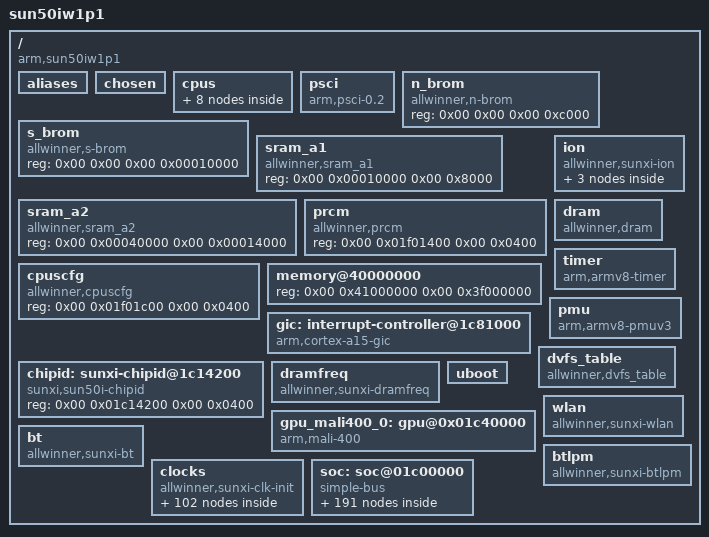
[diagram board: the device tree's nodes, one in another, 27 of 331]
/dts-v1/;

/memreserve/ 0x45000000 0x200000;
/memreserve/ 0x41010000 0x10000;
/memreserve/ 0x41020000 0x800;
/memreserve/ 0x40100000 0x4000;
/memreserve/ 0x40104000 0x1000;
/memreserve/ 0x40105000 0x1000;

/{
    model = "sun50iw1p1";
    compatible = "arm,sun50iw1p1", "arm,sun50iw1p1";
    interrupt-parent = <0x01>;
    #address-cells = <0x02>;
    #size-cells = <0x02>;

    aliases {
		serial0 = &uart0;
		serial1 = &uart1;
		serial2 = &uart2;
		serial3 = &uart3;
		serial4 = &uart4;
        twi0 = &twi0;
		s_twi0 = &s_twi0;
        twi1 = &twi1;
        twi2 = &twi2;
        spi0 = &spi0;
        spi1 = &spi1;
        global_timer0 = &soc_timer0;
        cci0 = &csi_cci0;
        csi_res0 = &csi_res0;
        vfe0 = &csi0;
        mmc0 = &sdc0;
        mmc2 = &sdc2;
        nand0 = &nand0;
        disp = &disp;
        lcd0 = &lcd0;
        hdmi = &hdmi;
        pwm = &pwm;
        pwm0 = &pwm0;
        s_pwm = &s_pwm; 
        spwm0 = &spwm0; 
        boot_disp = &boot_disp; 
    };

    chosen {
        bootargs = "earlyprintk=sunxi-uart,0x01c28000 loglevel=8 initcall_debug=1 console=ttyS0 init=/init";
        linux,initrd-start = <0x00 0x00>;
        linux,initrd-end = <0x00 0x00>;
    };

    cpus {
        #address-cells = <0x02>;
        #size-cells = <0x00>;

        cpu@0 {
            device_type = "cpu";
            compatible = "arm,cortex-a53", "arm,armv8";
            reg = <0x00 0x00>;
            enable-method = "psci";
            cpufreq_tbl = <0x00075300 0x000927c0 0x000afc80 
				0x000c7380 0x000dea80 0x000ea600 
				0x000f6180 0x00101d00 0x0010d880 
				0x00119400 0x00124f80 0x00148200>;
            clock-latency = <0x001e8480>;
            clock-frequency = <0x3c14dc00>;
            cpu-idle-states = <&CPU_SLEEP_0 &CLUSTER_SLEEP_0 &SYS_SLEEP_0>;
        };
        cpu@1 {
            device_type = "cpu";
            compatible = "arm,cortex-a53", "arm,armv8";
            reg = <0x00 0x01>;
            enable-method = "psci";
            clock-frequency = <0x3c14dc00>;
            cpu-idle-states = <&CPU_SLEEP_0 &CLUSTER_SLEEP_0 &SYS_SLEEP_0>;
        };
        cpu@2 {
            device_type = "cpu";
            compatible = "arm,cortex-a53", "arm,armv8";
            reg = <0x00 0x02>;
            enable-method = "psci";
            clock-frequency = <0x3c14dc00>;
            cpu-idle-states = <&CPU_SLEEP_0 &CLUSTER_SLEEP_0 &SYS_SLEEP_0>;
        };
        cpu@3 {
            device_type = "cpu";
            compatible = "arm,cortex-a53", "arm,armv8";
            reg = <0x00 0x03>;
            enable-method = "psci";
            clock-frequency = <0x3c14dc00>;
            cpu-idle-states = <&CPU_SLEEP_0 &CLUSTER_SLEEP_0 &SYS_SLEEP_0>;
        };
        idle-states {
            entry-method = "arm,psci";
            CPU_SLEEP_0: cpu-sleep-0 {
                compatible = "arm,idle-state";
                arm,psci-suspend-param = <0x00010000>;
                entry-latency-us = <0x28>;
                exit-latency-us = <0x64>;
                min-residency-us = <0x96>;
            };
            CLUSTER_SLEEP_0: cluster-sleep-0 {
                compatible = "arm,idle-state";
                arm,psci-suspend-param = <0x01010000>;
                entry-latency-us = <0x01f4>;
                exit-latency-us = <0x03e8>;
                min-residency-us = <0x09c4>;
           };
            SYS_SLEEP_0: sys-sleep-0 {
                compatible = "arm,idle-state";
                arm,psci-suspend-param = <0x02010000>;
                entry-latency-us = <0x03e8>;
                exit-latency-us = <0x07d0>;
                min-residency-us = <0x1194>;
            };
        };
    };
    psci {
        compatible = "arm,psci-0.2";
        method = "smc";
        psci_version = <0x84000000>;
        cpu_suspend = <0xc4000001>;
        cpu_off = <0x84000002>;
        cpu_on = <0xc4000003>;
        affinity_info = <0xc4000004>;
        migrate = <0xc4000005>;
        migrate_info_type = <0x84000006>;
        migrate_info_up_cpu = <0xc4000007>;
        system_off = <0x84000008>;
        system_reset = <0x84000009>;
    };
    n_brom {
        compatible = "allwinner,n-brom";
        reg = <0x00 0x00 0x00 0xc000>;
    };
    s_brom {
        compatible = "allwinner,s-brom";
        reg = <0x00 0x00 0x00 0x00010000>;
    };
    sram_a1 {
        compatible = "allwinner,sram_a1";
        reg = <0x00 0x00010000 0x00 0x8000>;
    };
    sram_a2 {
        compatible = "allwinner,sram_a2";
        reg = <0x00 0x00040000 0x00 0x00014000>;
    };
    prcm {
        compatible = "allwinner,prcm";
        reg = <0x00 0x01f01400 0x00 0x0400>;
    };
    cpuscfg {
        compatible = "allwinner,cpuscfg";
        reg = <0x00 0x01f01c00 0x00 0x0400>;
    };
    ion {
        compatible = "allwinner,sunxi-ion";
        system_contig {
            type = <0x01>;
        };
        cma {
            type = <0x04>;
        };
        system {
            type = <0x00>;
        };
    };
    dram {
        compatible = "allwinner,dram";
        clocks = <&clk_pll_ddr0>, <&clk_pll_ddr1>;
        clock-names = "pll_ddr0", "pll_ddr1";
        dram_clk = <0x02a0>;
        dram_type = <0x03>;
        dram_zq = <0x003b3bdd>;
        dram_odt_en = <0x01>;
        dram_para1 = <0x10e40400>;
        dram_para2 = <0x04000000>;
        dram_mr0 = <0x1c70>;
        dram_mr1 = <0x40>;
        dram_mr2 = <0x18>;
        dram_mr3 = <0x00>;
        dram_tpr0 = <0x0048a192>;
        dram_tpr1 = <0x01c2418d>;
        dram_tpr2 = <0x00076051>;
        dram_tpr3 = <0x050005dc>;
        dram_tpr4 = <0x00>;
        dram_tpr5 = <0x00>;
        dram_tpr6 = <0x00>;
        dram_tpr7 = <0x2a066198>;
        dram_tpr8 = <0x00>;
        dram_tpr9 = <0x00>;
        dram_tpr10 = <0x8808>;
        dram_tpr11 = <0x40a60066>;
        dram_tpr12 = <0x55550000>;
        dram_tpr13 = <0x04000903>;
        device_type = "dram";
    };
    memory@40000000 {
        device_type = "memory";
        reg = <0x00 0x41000000 0x00 0x3f000000>;
    };
    gic: interrupt-controller@1c81000 {
        compatible = "arm,cortex-a15-gic", "arm,cortex-a9-gic";
        #interrupt-cells = <0x03>;
        #address-cells = <0x00>;
        device_type = "gic";
        interrupt-controller;
        reg = <0x00 0x01c81000 0x00 0x1000 
		0x00 0x01c82000 0x00 0x2000 
		0x00 0x01c84000 0x00 0x2000 
		0x00 0x01c86000 0x00 0x2000>;
        interrupts = <0x01 0x09 0x0f04>;
        linux,phandle = <0x01>;
        phandle = <0x01>;
    };
    chipid: sunxi-chipid@1c14200 {
        compatible = "sunxi,sun50i-chipid";
        device_type = "chipid";
        reg = <0x00 0x01c14200 0x00 0x0400>;
    };
    timer {
        compatible = "arm,armv8-timer";
        interrupts = <0x01 0x0d 0xff01 
			0x01 0x0e 0xff01 
			0x01 0x0b 0xff01 
			0x01 0x0a 0xff01>;
        clock-frequency = <0x016e3600>;
    };
    pmu {
        compatible = "arm,armv8-pmuv3";
        interrupts = <0x00 0x78 0x04 
		0x00 0x79 0x04 
		0x00 0x7a 0x04 
		0x00 0x7b 0x04>;
    };
    dvfs_table: dvfs_table {
        compatible = "allwinner,dvfs_table";
        max_freq = <0x44aa2000>;
        min_freq = <0x1c9c3800>;
        lv_count = <0x08>;
        lv1_freq = <0x44aa2000>;
        lv1_volt = <0x0514>;
        lv2_freq = <0x41cdb400>;
        lv2_volt = <0x04ec>;
        lv3_freq = <0x3ef14800>;
        lv3_volt = <0x04d8>;
        lv4_freq = <0x3c14dc00>;
        lv4_volt = <0x04b0>;
        lv5_freq = <0x39387000>;
        lv5_volt = <0x0488>;
        lv6_freq = <0x365c0400>;
        lv6_volt = <0x0460>;
        lv7_freq = <0x30a32c00>;
        lv7_volt = <0x0438>;
        lv8_freq = <0x269fb200>;
        lv8_volt = <0x0410>;
        device_type = "dvfs_table";
    };
    dramfreq {
        compatible = "allwinner,sunxi-dramfreq";
        reg = <0x00 0x01c62000 0x00 
			0x1000 0x00 0x01c63000 
			0x00 0x1000 0x00 
			0x01c20000 0x00 0x0800>;
        clocks = <&clk_pll_ddr0>, <&clk_pll_ddr1>, <&clk_ahb1>;
        status = "okay";
    };

    uboot: uboot {
    };

    gpu_mali400_0: gpu@0x01c40000 {
        compatible = "arm,mali-400", "arm,mali-utgard";
        reg = <0x00 0x01c40000 0x00 0x00010000>;
        interrupts = <0x00 0x61 0x04 
			0x00 0x62 0x04 
			0x00 0x63 0x04 
			0x00 0x64 0x04 
			0x00 0x66 0x04 
			0x00 0x67 0x04>;
        interrupt-names = "IRQGP", "IRQGPMMU", "IRQPP0", 
			"IRQPPMMU0", "IRQPP1", "IRQPPMMU1";
        clocks = <&clk_pll_gpu>, <&clk_gpu>;
        device_type = "gpu_mali400_0";
        normal_freq = <0x0198>;
        scene_ctrl_status = <0x00>;
        temp_ctrl_status = <0x01>;
    };
    wlan: wlan {
        compatible = "allwinner,sunxi-wlan";
        wlan_io_regulator = "vcc-wifi-io";
        wlan_busnum = <0x01>;
        status = "okay";
        device_type = "wlan";
        clocks;
        wlan_power;
        wlan_regon = <&r_pio 0x0b 0x02 0x01 0xffffffff 0xffffffff 0x00>;
        wlan_hostwake = <&r_pio 0x0b 0x03 0x06 0xffffffff 0xffffffff 0x00>;
        efuse_map_path = "wifi_efuse_8189e_for_MB1019Q5.map";
    };
    bt: bt {
        compatible = "allwinner,sunxi-bt";
        bt_io_regulator = "vcc-wifi-io";
        status = "okay";
        device_type = "bt";
        clocks;
        bt_power;
        bt_rst_n = <&r_pio 0x0b 0x04 0x01 0xffffffff 0xffffffff 0x00>;
    };
    btlpm: btlpm {
        compatible = "allwinner,sunxi-btlpm";
        uart_index = <0x01>;
        status = "okay";
        device_type = "btlpm";
        bt_wake = <&r_pio 0x0b 0x06 0x01 0xffffffff 0xffffffff 0x01>;
        bt_hostwake = <&r_pio 0x0b 0x05 0x06 0xffffffff 0xffffffff 0x00>;
    };

	/*** Clocks configuration  ***/
    clocks {
        compatible = "allwinner,sunxi-clk-init";
        device_type = "clocks";
        #address-cells = <0x02>;
        #size-cells = <0x02>;
        ranges;
        reg = <0x00 0x01c20000 0x00 
			0x0320 0x00 0x01f01400 
			0x00 0xb0 0x00 
			0x01f00060 0x00 0x04>;

        clk_losc: losc {
            #clock-cells = <0x00>;
            compatible = "allwinner,fixed-clock";
            clock-frequency = <0x8000>;
            clock-output-names = "losc";
            linux,phandle = <0x0c>;
            phandle = <0x0c>;
        };

        clk_iosc: iosc {
            #clock-cells = <0x00>;
            compatible = "allwinner,fixed-clock";
            clock-frequency = <0x00f42400>;
            clock-output-names = "iosc";
            linux,phandle = <0x0d>;
            phandle = <0x0d>;
        };

        clk_hosc: hosc {
            #clock-cells = <0x00>;
            compatible = "allwinner,fixed-clock";
            clock-frequency = <0x016e3600>;
            clock-output-names = "hosc";
            linux,phandle = <0x06>;
            phandle = <0x06>;
        };

        clk_pll_cpu: pll_cpu {
            #clock-cells = <0x00>;
            compatible = "allwinner,sunxi-pll-clock";
            lock-mode = "new";
            clock-output-names = "pll_cpu";
        };

        clk_pll_audio: pll_audio {
            #clock-cells = <0x00>;
            compatible = "allwinner,sunxi-pll-clock";
            lock-mode = "new";
            assigned-clock-rates = <0x01770000>;
            clock-output-names = "pll_audio";
            linux,phandle = <0x02>;
            phandle = <0x02>;
        };

        clk_pll_video0: pll_video0 {
            #clock-cells = <0x00>;
            compatible = "allwinner,sunxi-pll-clock";
            lock-mode = "new";
            assigned-clock-rates = <0x11b3dc40>;
            clock-output-names = "pll_video0";
            linux,phandle = <0x03>;
            phandle = <0x03>;
        };

        clk_pll_ve: pll_ve {
            #clock-cells = <0x00>;
            compatible = "allwinner,sunxi-pll-clock";
            lock-mode = "new";
            clock-output-names = "pll_ve";
            linux,phandle = <0x16>;
            phandle = <0x16>;
        };
        clk_pll_ddr0: pll_ddr0 {
            #clock-cells = <0x00>;
            compatible = "allwinner,sunxi-pll-clock";
            lock-mode = "new";
            clock-output-names = "pll_ddr0";
            linux,phandle = <0x93>;
            phandle = <0x93>;
        };

        clk_pll_periph0: pll_periph0 {
            #clock-cells = <0x00>;
            compatible = "allwinner,sunxi-pll-clock";
            lock-mode = "new";
            clock-output-names = "pll_periph0";
            linux,phandle = <0x04>;
            phandle = <0x04>;
        };

        clk_pll_periph1: pll_periph1 {
            #clock-cells = <0x00>;
            compatible = "allwinner,sunxi-pll-clock";
            lock-mode = "new";
            clock-output-names = "pll_periph1";
            linux,phandle = <0x05>;
            phandle = <0x05>;
        };

        clk_pll_video1: pll_video1 {
            #clock-cells = <0x00>;
            compatible = "allwinner,sunxi-pll-clock";
            lock-mode = "new";
            assigned-clock-rates = <0x11b3dc40>;
            clock-output-names = "pll_video1";
        };

        clk_pll_gpu: pll_gpu {
            #clock-cells = <0x00>;
            compatible = "allwinner,sunxi-pll-clock";
            lock-mode = "new";
            clock-output-names = "pll_gpu";
            linux,phandle = <0x96>;
            phandle = <0x96>;
        };

        clk_pll_mipi: pll_mipi {
            #clock-cells = <0x00>;
            compatible = "allwinner,sunxi-pll-clock";
            lock-mode = "new";
            clock-output-names = "pll_mipi";
            linux,phandle = <0x08>;
            phandle = <0x08>;
        };
		
        clk_pll_hsic: pll_hsic {
            #clock-cells = <0x00>;
            compatible = "allwinner,sunxi-pll-clock";
            lock-mode = "new";
            clock-output-names = "pll_hsic";
            linux,phandle = <0x3a>;
            phandle = <0x3a>;
        };

        clk_pll_de: pll_de {
            #clock-cells = <0x00>;
            compatible = "allwinner,sunxi-pll-clock";
            lock-mode = "new";
            assigned-clock-rates = <0x11b3dc40>;
            clock-output-names = "pll_de";
            linux,phandle = <0x07>;
            phandle = <0x07>;
        };

        clk_pll_ddr1: pll_ddr1 {
            #clock-cells = <0x00>;
            compatible = "allwinner,sunxi-pll-clock";
            lock-mode = "new";
            clock-output-names = "pll_ddr1";
            linux,phandle = <0x94>;
            phandle = <0x94>;
        };

        clk_pll_audiox8: pll_audiox8 {
            #clock-cells = <0x00>;
            compatible = "allwinner,fixed-factor-clock";
            clocks = <0x02>;
            clock-mult = <0x08>;
            clock-div = <0x01>;
            clock-output-names = "pll_audiox8";
        };

        clk_pll_audiox4: pll_audiox4 {
            #clock-cells = <0x00>;
            compatible = "allwinner,fixed-factor-clock";
            clocks = <0x02>;
            clock-mult = <0x08>;
            clock-div = <0x02>;
            clock-output-names = "pll_audiox4";
            linux,phandle = <0x3c>;
            phandle = <0x3c>;
        };

        clk_pll_audiox2: pll_audiox2 {
            #clock-cells = <0x00>;
            compatible = "allwinner,fixed-factor-clock";
            clocks = <0x02>;
            clock-mult = <0x08>;
            clock-div = <0x04>;
            clock-output-names = "pll_audiox2";
        };

        clk_pll_video0x2: pll_video0x2 {
            #clock-cells = <0x00>;
            compatible = "allwinner,fixed-factor-clock";
            clocks = <0x03>;
            clock-mult = <0x02>;
            clock-div = <0x01>;
            clock-output-names = "pll_video0x2";
        };

        clk_pll_periph0x2: pll_periph0x2 {
            #clock-cells = <0x00>;
            compatible = "allwinner,fixed-factor-clock";
            clocks = <0x04>;
            clock-mult = <0x02>;
            clock-div = <0x01>;
            clock-output-names = "pll_periph0x2";
            linux,phandle = <0x7b>;
            phandle = <0x7b>;
        };

        clk_pll_periph1x2: pll_periph1x2 {
            #clock-cells = <0x00>;
            compatible = "allwinner,fixed-factor-clock";
            clocks = <0x05>;
            clock-mult = <0x02>;
            clock-div = <0x01>;
            clock-output-names = "pll_periph1x2";
            linux,phandle = <0x5a>;
            phandle = <0x5a>;
        };

        clk_pll_periph0d2: pll_periph0d2 {
            #clock-cells = <0x00>;
            compatible = "allwinner,fixed-factor-clock";
            clocks = <0x04>;
            clock-mult = <0x01>;
            clock-div = <0x02>;
            clock-output-names = "pll_periph0d2";
        };

        clk_hoscd2: hoscd2 {
            #clock-cells = <0x00>;
            compatible = "allwinner,fixed-factor-clock";
            clocks = <0x06>;
            clock-mult = <0x01>;
            clock-div = <0x02>;
            clock-output-names = "hoscd2";
        };

        clk_cpu: cpu {
            #clock-cells = <0x00>;
            compatible = "allwinner,sunxi-periph-clock";
            clock-output-names = "cpu";
        };

        clk_cpuapb: cpuapb {
            #clock-cells = <0x00>;
            compatible = "allwinner,sunxi-periph-clock";
            clock-output-names = "cpuapb";
        };

        clk_axi: axi {
            #clock-cells = <0x00>;
            compatible = "allwinner,sunxi-periph-clock";
            clock-output-names = "axi";
        };

        clk_pll_periphahb0: pll_periphahb0 {
            #clock-cells = <0x00>;
            compatible = "allwinner,sunxi-periph-clock";
            clock-output-names = "pll_periphahb0";
        };

        clk_ahb1: ahb1 {
            #clock-cells = <0x00>;
            compatible = "allwinner,sunxi-periph-clock";
            clock-output-names = "ahb1";
            linux,phandle = <0x95>;
            phandle = <0x95>;
        };

        clk_apb1: apb1 {
            #clock-cells = <0x00>;
            compatible = "allwinner,sunxi-periph-clock";
            clock-output-names = "apb1";
        };

        clk_apb2: apb2 {
            #clock-cells = <0x00>;
            compatible = "allwinner,sunxi-periph-clock";
            clock-output-names = "apb2";
            linux,phandle = <0x7e>;
            phandle = <0x7e>;
        };

        clk_ahb2: ahb2 {
            #clock-cells = <0x00>;
            compatible = "allwinner,sunxi-periph-clock";
            clock-output-names = "ahb2";
        };

        clk_ths: ths {
            #clock-cells = <0x00>;
            compatible = "allwinner,sunxi-periph-clock";
            clock-output-names = "ths";
            linux,phandle = <0x84>;
            phandle = <0x84>;
        };

        clk_nand: nand {
            #clock-cells = <0x00>;
            compatible = "allwinner,sunxi-periph-clock";
            clock-output-names = "nand";
            linux,phandle = <0x80>;
            phandle = <0x80>;
        };
		
        clk_sdmmc0_mod: sdmmc0_mod {
            #clock-cells = <0x00>;
            compatible = "allwinner,sunxi-periph-clock";
            clock-output-names = "sdmmc0_mod";
            linux,phandle = <0x60>;
            phandle = <0x60>;
        };

        clk_sdmmc0_bus: sdmmc0_bus {
            #clock-cells = <0x00>;
            compatible = "allwinner,sunxi-periph-clock";
            clock-output-names = "sdmmc0_bus";
            linux,phandle = <0x61>;
            phandle = <0x61>;
        };

        clk_sdmmc0_rst: sdmmc0_rst {
            #clock-cells = <0x00>;
            compatible = "allwinner,sunxi-periph-clock";
            clock-output-names = "sdmmc0_rst";
            linux,phandle = <0x62>;
            phandle = <0x62>;
        };

        clk_sdmmc1_mod: sdmmc1_mod {
            #clock-cells = <0x00>;
            compatible = "allwinner,sunxi-periph-clock";
            clock-output-names = "sdmmc1_mod";
            linux,phandle = <0x65>;
            phandle = <0x65>;
        };

        clk_sdmmc1_bus: sdmmc1_bus {
            #clock-cells = <0x00>;
            compatible = "allwinner,sunxi-periph-clock";
            clock-output-names = "sdmmc1_bus";
            linux,phandle = <0x66>;
            phandle = <0x66>;
        };

        clk_sdmmc1_rst: sdmmc1_rst {
            #clock-cells = <0x00>;
            compatible = "allwinner,sunxi-periph-clock";
            clock-output-names = "sdmmc1_rst";
            linux,phandle = <0x67>;
            phandle = <0x67>;
        };
		
        clk_sdmmc2_mod: sdmmc2_mod {
            #clock-cells = <0x00>;
            compatible = "allwinner,sunxi-periph-clock";
            clock-output-names = "sdmmc2_mod";
            linux,phandle = <0x5b>;
            phandle = <0x5b>;
        };

        clk_sdmmc2_bus: sdmmc2_bus {
            #clock-cells = <0x00>;
            compatible = "allwinner,sunxi-periph-clock";
            clock-output-names = "sdmmc2_bus";
            linux,phandle = <0x5c>;
            phandle = <0x5c>;
        };

        clk_sdmmc2_rst: sdmmc2_rst {
            #clock-cells = <0x00>;
            compatible = "allwinner,sunxi-periph-clock";
            clock-output-names = "sdmmc2_rst";
            linux,phandle = <0x5d>;
            phandle = <0x5d>;
        };

        clk_ts: ts {
            #clock-cells = <0x00>;
            compatible = "allwinner,sunxi-periph-clock";
            clock-output-names = "ts";
        };

        clk_ce: ce {
            #clock-cells = <0x00>;
            compatible = "allwinner,sunxi-periph-clock";
            clock-output-names = "ce";
            linux,phandle = <0x7a>;
            phandle = <0x7a>;
        };

        clk_spi0: spi0 {
            #clock-cells = <0x00>;
            compatible = "allwinner,sunxi-periph-clock";
            clock-output-names = "spi0";
            linux,phandle = <0x52>;
            phandle = <0x52>;
        };

        clk_spi1: spi1 {
            #clock-cells = <0x00>;
            compatible = "allwinner,sunxi-periph-clock";
            clock-output-names = "spi1";
            linux,phandle = <0x56>;
            phandle = <0x56>;
        };

        clk_i2s0: i2s0 {
            #clock-cells = <0x00>;
            compatible = "allwinner,sunxi-periph-clock";
            clock-output-names = "i2s0";
            linux,phandle = <0x42>;
            phandle = <0x42>;
        };

        clk_i2s1: i2s1 {
            #clock-cells = <0x00>;
            compatible = "allwinner,sunxi-periph-clock";
            clock-output-names = "i2s1";
            linux,phandle = <0x47>;
            phandle = <0x47>;
        };

        clk_i2s2: i2s2 {
            #clock-cells = <0x00>;
            compatible = "allwinner,sunxi-periph-clock";
            clock-output-names = "i2s2";
            linux,phandle = <0x48>;
            phandle = <0x48>;
        };

        clk_spdif: spdif {
            #clock-cells = <0x00>;
            compatible = "allwinner,sunxi-periph-clock";
            clock-output-names = "spdif";
            linux,phandle = <0x49>;
            phandle = <0x49>;
        };

        clk_usbphy0: usbphy0 {
            #clock-cells = <0x00>;
            compatible = "allwinner,sunxi-periph-clock";
            clock-output-names = "usbphy0";
            linux,phandle = <0x32>;
            phandle = <0x32>;
        };

        clk_usbphy1: usbphy1 {
            #clock-cells = <0x00>;
            compatible = "allwinner,sunxi-periph-clock";
            clock-output-names = "usbphy1";
            linux,phandle = <0x36>;
            phandle = <0x36>;
        };

        clk_usbhsic: usbhsic {
            #clock-cells = <0x00>;
            compatible = "allwinner,sunxi-periph-clock";
            clock-output-names = "usbhsic";
            linux,phandle = <0x38>;
            phandle = <0x38>;
        };

        clk_usbhsic12m: usbhsic12m {
            #clock-cells = <0x00>;
            compatible = "allwinner,sunxi-periph-clock";
            clock-output-names = "usbhsic12m";
            linux,phandle = <0x39>;
            phandle = <0x39>;
        };

        clk_usbohci1: usbohci1 {
            #clock-cells = <0x00>;
            compatible = "allwinner,sunxi-periph-clock";
            clock-output-names = "usbohci1";
            linux,phandle = <0x3b>;
            phandle = <0x3b>;
        };

        clk_usbohci0: usbohci0 {
            #clock-cells = <0x00>;
            compatible = "allwinner,sunxi-periph-clock";
            clock-output-names = "usbohci0";
            linux,phandle = <0x35>;
            phandle = <0x35>;
        };

        clk_de: de {
            #clock-cells = <0x00>;
            compatible = "allwinner,sunxi-periph-clock";
            assigned-clock-parents = <0x07>;
            assigned-clock-rates = <0x11b3dc40>;
            clock-output-names = "de";
            linux,phandle = <0x6a>;
            phandle = <0x6a>;
        };

        clk_tcon0: tcon0 {
            #clock-cells = <0x00>;
            compatible = "allwinner,sunxi-periph-clock";
            assigned-clock-parents = <0x08>;
            clock-output-names = "tcon0";
            linux,phandle = <0x6b>;
            phandle = <0x6b>;
        };

        clk_tcon1: tcon1 {
            #clock-cells = <0x00>;
            compatible = "allwinner,sunxi-periph-clock";
            assigned-clock-parents = <0x03>;
            clock-output-names = "tcon1";
            linux,phandle = <0x6e>;
            phandle = <0x6e>;
        };

        clk_deinterlace: deinterlace {
            #clock-cells = <0x00>;
            compatible = "allwinner,sunxi-periph-clock";
            clock-output-names = "deinterlace";
            linux,phandle = <0x7c>;
            phandle = <0x7c>;
        };

        clk_csi_s: csi_s {
            #clock-cells = <0x00>;
            compatible = "allwinner,sunxi-periph-clock";
            clock-output-names = "csi_s";
            linux,phandle = <0x73>;
            phandle = <0x73>;
        };

        clk_csi_m: csi_m {
            #clock-cells = <0x00>;
            compatible = "allwinner,sunxi-periph-clock";
            clock-output-names = "csi_m";
            linux,phandle = <0x74>;
            phandle = <0x74>;
        };

        clk_csi_misc: csi_misc {
            #clock-cells = <0x00>;
            compatible = "allwinner,sunxi-periph-clock";
            clock-output-names = "csi_misc";
            linux,phandle = <0x75>;
            phandle = <0x75>;
        };

        clk_ve: ve {
            #clock-cells = <0x00>;
            compatible = "allwinner,sunxi-periph-clock";
            clock-output-names = "ve";
            linux,phandle = <0x17>;
            phandle = <0x17>;
        };

        clk_adda: adda {
            #clock-cells = <0x00>;
            compatible = "allwinner,sunxi-periph-clock";
            clock-output-names = "adda";
            linux,phandle = <0x41>;
            phandle = <0x41>;
        };

        clk_addax4: addax4 {
            #clock-cells = <0x00>;
            compatible = "allwinner,sunxi-periph-clock";
            clock-output-names = "addax4";
        };

        clk_avs: avs {
            #clock-cells = <0x00>;
            compatible = "allwinner,sunxi-periph-clock";
            clock-output-names = "avs";
        };

        clk_hdmi: hdmi {
            #clock-cells = <0x00>;
            compatible = "allwinner,sunxi-periph-clock";
            assigned-clock-parents = <0x03>;
            clock-output-names = "hdmi";
            linux,phandle = <0x6f>;
            phandle = <0x6f>;
        };

        clk_hdmi_slow: hdmi_slow {
            #clock-cells = <0x00>;
            compatible = "allwinner,sunxi-periph-clock";
            clock-output-names = "hdmi_slow";
            linux,phandle = <0x70>;
            phandle = <0x70>;
        };

        clk_mbus: mbus {
            #clock-cells = <0x00>;
            compatible = "allwinner,sunxi-periph-clock";
            clock-output-names = "mbus";
        };

        clk_mipidsi: mipidsi {
            #clock-cells = <0x00>;
            compatible = "allwinner,sunxi-periph-clock";
            clock-output-names = "mipidsi";
            linux,phandle = <0x6d>;
            phandle = <0x6d>;
        };

        clk_gpu: gpu {
            #clock-cells = <0x00>;
            compatible = "allwinner,sunxi-periph-clock";
            clock-output-names = "gpu";
            linux,phandle = <0x97>;
            phandle = <0x97>;
        };

        clk_usbehci_16: usbehci_16 {
            #clock-cells = <0x00>;
            compatible = "allwinner,sunxi-periph-clock";
            clock-output-names = "usbohci_16";
        };

        clk_usbehci1: usbehci1 {
            #clock-cells = <0x00>;
            compatible = "allwinner,sunxi-periph-clock";
            clock-output-names = "usbehci1";
            linux,phandle = <0x37>;
            phandle = <0x37>;
        };

        clk_usbehci0: usbehci0 {
            #clock-cells = <0x00>;
            compatible = "allwinner,sunxi-periph-clock";
            clock-output-names = "usbehci0";
            linux,phandle = <0x34>;
            phandle = <0x34>;
        };

        clk_usbotg: usbotg {
            #clock-cells = <0x00>;
            compatible = "allwinner,sunxi-periph-clock";
            clock-output-names = "usbotg";
            linux,phandle = <0x33>;
            phandle = <0x33>;
        };

        clk_gmac: gmac {
            #clock-cells = <0x00>;
            compatible = "allwinner,sunxi-periph-clock";
            clock-output-names = "gmac";
            linux,phandle = <0x8f>;
            phandle = <0x8f>;
        };

        clk_sdram: sdram {
            #clock-cells = <0x00>;
            compatible = "allwinner,sunxi-periph-clock";
            clock-output-names = "sdram";
        };

        clk_dma: dma {
            #clock-cells = <0x00>;
            compatible = "allwinner,sunxi-periph-clock";
            clock-output-names = "dma";
            linux,phandle = <0x0b>;
            phandle = <0x0b>;
        };

        clk_hwspinlock_rst: hwspinlock_rst {
            #clock-cells = <0x00>;
            compatible = "allwinner,sunxi-periph-clock";
            clock-output-names = "hwspinlock_rst";
            linux,phandle = <0x0f>;
            phandle = <0x0f>;
        };

        clk_hwspinlock_bus: hwspinlock_bus {
            #clock-cells = <0x00>;
            compatible = "allwinner,sunxi-periph-clock";
            clock-output-names = "hwspinlock_bus";
            linux,phandle = <0x10>;
            phandle = <0x10>;
        };

        clk_msgbox: msgbox {
            #clock-cells = <0x00>;
            compatible = "allwinner,sunxi-periph-clock";
            clock-output-names = "msgbox";
            linux,phandle = <0x0e>;
            phandle = <0x0e>;
        };

        clk_lvds: lvds {
            #clock-cells = <0x00>;
            compatible = "allwinner,sunxi-periph-clock";
            clock-output-names = "lvds";
            linux,phandle = <0x6c>;
            phandle = <0x6c>;
        };

        clk_uart0: uart0 {
            #clock-cells = <0x00>;
            compatible = "allwinner,sunxi-periph-clock";
            clock-output-names = "uart0";
            linux,phandle = <0x18>;
            phandle = <0x18>;
        };

        clk_uart1: uart1 {
            #clock-cells = <0x00>;
            compatible = "allwinner,sunxi-periph-clock";
            clock-output-names = "uart1";
            linux,phandle = <0x1b>;
            phandle = <0x1b>;
        };

        clk_uart2: uart2 {
            #clock-cells = <0x00>;
            compatible = "allwinner,sunxi-periph-clock";
            clock-output-names = "uart2";
            linux,phandle = <0x1e>;
            phandle = <0x1e>;
        };

        clk_uart3: uart3 {
            #clock-cells = <0x00>;
            compatible = "allwinner,sunxi-periph-clock";
            clock-output-names = "uart3";
            linux,phandle = <0x21>;
            phandle = <0x21>;
        };

        clk_uart4: uart4 {
            #clock-cells = <0x00>;
            compatible = "allwinner,sunxi-periph-clock";
            clock-output-names = "uart4";
            linux,phandle = <0x24>;
            phandle = <0x24>;
        };

        clk_scr: scr {
            #clock-cells = <0x00>;
            compatible = "allwinner,sunxi-periph-clock";
            clock-output-names = "scr";
            linux,phandle = <0x7d>;
            phandle = <0x7d>;
        };

        clk_twi0: twi0 {
            #clock-cells = <0x00>;
            compatible = "allwinner,sunxi-periph-clock";
            clock-output-names = "twi0";
            linux,phandle = <0x27>;
            phandle = <0x27>;
        };

        clk_twi1: twi1 {
            #clock-cells = <0x00>;
            compatible = "allwinner,sunxi-periph-clock";
            clock-output-names = "twi1";
            linux,phandle = <0x2a>;
            phandle = <0x2a>;
        };

        clk_twi2: twi2 {
            #clock-cells = <0x00>;
            compatible = "allwinner,sunxi-periph-clock";
            clock-output-names = "twi2";
            linux,phandle = <0x2d>;
            phandle = <0x2d>;
        };

        clk_twi3: twi3 {
            #clock-cells = <0x00>;
            compatible = "allwinner,sunxi-periph-clock";
            clock-output-names = "twi3";
        };

        clk_pio: pio {
            #clock-cells = <0x00>;
            compatible = "allwinner,sunxi-periph-clock";
            clock-output-names = "pio";
            linux,phandle = <0x0a>;
            phandle = <0x0a>;
        };

        clk_cpurcir: cpurcir {
            #clock-cells = <0x00>;
            compatible = "allwinner,sunxi-periph-cpus-clock";
            clock-output-names = "cpurcir";
            linux,phandle = <0x12>;
            phandle = <0x12>;
        };

        clk_cpurpio: cpurpio {
            #clock-cells = <0x00>;
            compatible = "allwinner,sunxi-periph-cpus-clock";
            clock-output-names = "cpurpio";
            linux,phandle = <0x09>;
            phandle = <0x09>;
        };

        clk_cpurpll_peri0: cpurpll_peri0 {
            #clock-cells = <0x00>;
            compatible = "allwinner,sunxi-periph-cpus-clock";
            clock-output-names = "cpurpll_peri0";
        };

        clk_cpurcpus: cpurcpus {
            #clock-cells = <0x00>;
            compatible = "allwinner,sunxi-periph-cpus-clock";
            clock-output-names = "cpurcpus";
        };

        clk_cpurahbs: cpurahbs {
            #clock-cells = <0x00>;
            compatible = "allwinner,sunxi-periph-cpus-clock";
            clock-output-names = "cpurahbs";
        };

        clk_cpuapbs: cpurapbs {
            #clock-cells = <0x00>;
            compatible = "allwinner,sunxi-periph-cpus-clock";
            clock-output-names = "cpurapbs";
        };

        clk_losc_out: losc_out {
            #clock-cells = <0x00>;
            compatible = "allwinner,sunxi-periph-cpus-clock";
            clock-output-names = "losc_out";
            linux,phandle = <0x98>;
            phandle = <0x98>;
        };
    };

	/***  SOC Configuration ***/
    soc: soc@01c00000 {
        compatible = "simple-bus";
        #address-cells = <0x02>;
        #size-cells = <0x02>;
        ranges;
        device_type = "soc";

		/*** Pin control (r_pio) ***/
        r_pio: pinctrl@01f02c00 {
            compatible = "allwinner,sun50i-r-pinctrl";
            reg = <0x00 0x01f02c00 0x00 0x0400>;
            interrupts = <0x00 0x2d 0x04>;
            clocks = <0x09>;
            device_type = "r_pio";
            gpio-controller;
            interrupt-controller;
            #interrupt-cells = <0x02>;
            #size-cells = <0x00>;
            #gpio-cells = <0x06>;
            linux,phandle = <0x79>;
            phandle = <0x79>;

            s_cir0_pins_a: s_cir0@0 {
                allwinner,pins = "L11";
                allwinner,function = "s_cir0";
                allwinner,muxsel = <0x02>;
                allwinner,drive = <0x02>;
                allwinner,pull = <0x01>;
                linux,phandle = <0x11>;
                phandle = <0x11>;
            };

            spwm0_pins_a: spwm0@0 {
                linux,phandle = <0xaf>;
                phandle = <0xaf>;
                allwinner,pins = "PL10";
                allwinner,function = "spwm0";
                allwinner,pname = "pwm_positive";
                allwinner,muxsel = <0x02>;
                allwinner,pull = <0x00>;
                allwinner,drive = <0xffffffff>;
                allwinner,data = <0xffffffff>;
            };

            spwm0_pins_b: spwm0@1 {
                linux,phandle = <0xb0>;
                phandle = <0xb0>;
                allwinner,pins = "PL10";
                allwinner,function = "spwm0";
                allwinner,pname = "pwm_positive";
                allwinner,muxsel = <0x07>;
                allwinner,pull = <0x00>;
                allwinner,drive = <0xffffffff>;
                allwinner,data = <0xffffffff>;
            };

            s_uart0_pins_a: s_uart0@0 {
                linux,phandle = <0xb6>;
                phandle = <0xb6>;
                allwinner,pins = "PL2", "PL3";
                allwinner,function = "s_uart0";
                allwinner,pname = "s_uart0_tx", "s_uart0_rx";
                allwinner,muxsel = <0x02>;
                allwinner,pull = <0xffffffff>;
                allwinner,drive = <0xffffffff>;
                allwinner,data = <0xffffffff>;
            };

            s_rsb0_pins_a: s_rsb0@0 {
                linux,phandle = <0xb7>;
                phandle = <0xb7>;
                allwinner,pins = "PL0", "PL1";
                allwinner,function = "s_rsb0";
                allwinner,pname = "s_rsb0_sck", "s_rsb0_sda";
                allwinner,muxsel = <0x02>;
                allwinner,pull = <0x01>;
                allwinner,drive = <0x02>;
                allwinner,data = <0xffffffff>;
            };

            s_jtag0_pins_a: s_jtag0@0 {
                linux,phandle = <0xb8>;
                phandle = <0xb8>;
                allwinner,pins = "PL4", "PL5", "PL6", "PL7";
                allwinner,function = "s_jtag0";
                allwinner,pname = "s_jtag0_tms", "s_jtag0_tck", "s_jtag0_tdo", "s_jtag0_tdi";
                allwinner,muxsel = <0x02>;
                allwinner,pull = <0x00>;
                allwinner,drive = <0x01>;
                allwinner,data = <0xffffffff>;
            };

            s_twi0_pins_a: s_twi0@0 {
                allwinner,pins = "PL8", "PL9";
                allwinner,function = "s_twi0";
                allwinner,pname = "s_twi0_scl", "s_twi0_sda";
                allwinner,muxsel = <0x02>;
                allwinner,pull = <0x00>;
                allwinner,drive = <0x01>;
                allwinner,data = <0xffffffff>;
            };

            s_twi0_pins_b: s_twi0@1 {
                allwinner,pins = "PL8", "PL9";
                allwinner,function = "io_disabled";
                allwinner,muxsel = <0x07>;
                allwinner,drive = <0x01>;
                allwinner,pull = <0x00>;
            };


        };

		/*** Pin control (pio) ***/
        pio: pinctrl@01c20800 {
            compatible = "allwinner,sun50i-pinctrl";
            reg = <0x00 0x01c20800 0x00 0x0400>;
            interrupts = <0x00 0x0b 0x04 
				0x00 0x11 0x04 
				0x00 0x15 0x04>;
            device_type = "pio";
            clocks = <0x0a>;
            gpio-controller;
            interrupt-controller;
            #interrupt-cells = <0x02>;
            #size-cells = <0x00>;
            #gpio-cells = <0x06>;
            linux,phandle = <0x30>;
            phandle = <0x30>;

            uart0_pins_b: uart0@1 {
                allwinner,pins = "PB8", "PB9";
                allwinner,function = "io_disabled";
                allwinner,muxsel = <0x07>;
                allwinner,drive = <0x01>;
                allwinner,pull = <0x01>;
                linux,phandle = <0x1a>;
                phandle = <0x1a>;
            };

            uart1_pins_b: uart1@1 {
                allwinner,pins = "PG6", "PG7", "PG8", "PG9";
                allwinner,function = "io_disabled";
                allwinner,muxsel = <0x07>;
                allwinner,drive = <0x01>;
                allwinner,pull = <0x01>;
                linux,phandle = <0x1d>;
                phandle = <0x1d>;
            };

            uart2_pins_b: uart2@1 {
                allwinner,pins = "PB0", "PB1", "PB2", "PB3";
                allwinner,function = "io_disabled";
                allwinner,muxsel = <0x07>;
                allwinner,drive = <0x01>;
                allwinner,pull = <0x01>;
                linux,phandle = <0x20>;
                phandle = <0x20>;
            };

            uart3_pins_b: uart3@1 {
                allwinner,pins = "PH4", "PH5", "PH6", "PH7";
                allwinner,function = "io_disabled";
                allwinner,muxsel = <0x07>;
                allwinner,drive = <0x01>;
                allwinner,pull = <0x01>;
                linux,phandle = <0x23>;
                phandle = <0x23>;
            };

            uart4_pins_b: uart4@1 {
                allwinner,pins = "PD2", "PD3", "PD4", "PD5";
                allwinner,function = "io_disabled";
                allwinner,muxsel = <0x07>;
                allwinner,drive = <0x01>;
                allwinner,pull = <0x01>;
                linux,phandle = <0x26>;
                phandle = <0x26>;
            };

            twi0_pins_b: twi0@1 {
                allwinner,pins = "PH0", "PH1";
                allwinner,function = "io_disabled";
                allwinner,muxsel = <0x07>;
                allwinner,drive = <0x01>;
                allwinner,pull = <0x00>;
                linux,phandle = <0x29>;
                phandle = <0x29>;
            };

            twi1_pins_b: twi1@1 {
                allwinner,pins = "PH2", "PH3";
                allwinner,function = "io_disabled";
                allwinner,muxsel = <0x07>;
                allwinner,drive = <0x01>;
                allwinner,pull = <0x00>;
                linux,phandle = <0x2c>;
                phandle = <0x2c>;
            };

            twi2_pins_b: twi2@1 {
                allwinner,pins = "PE14", "PE15";
                allwinner,function = "io_disabled";
                allwinner,muxsel = <0x07>;
                allwinner,drive = <0x01>;
                allwinner,pull = <0x00>;
                linux,phandle = <0x2f>;
                phandle = <0x2f>;
            };

            spi0_pins_c: spi0@2 {
                allwinner,pins = "PC3", "PC2", "PC0", "PC1";
                allwinner,function = "io_disabled";
                allwinner,muxsel = <0x07>;
                allwinner,drive = <0x01>;
                allwinner,pull = <0x00>;
                linux,phandle = <0x55>;
                phandle = <0x55>;
            };

            spi1_pins_c: spi1@2 {
                allwinner,pins = "PD0", "PD1", "PD2", "PD3";
                allwinner,function = "io_disabled";
                allwinner,muxsel = <0x07>;
                allwinner,drive = <0x01>;
                allwinner,pull = <0x00>;
                linux,phandle = <0x59>;
                phandle = <0x59>;
            };

            sdc0_pins_b: sdc0@1 {
                allwinner,pins = "PF0", "PF1", "PF2", "PF3", "PF4", "PF5";
                allwinner,function = "io_disabled";
                allwinner,muxsel = <0x07>;
                allwinner,drive = <0x01>;
                allwinner,pull = <0x01>;
                linux,phandle = <0x64>;
                phandle = <0x64>;
            };

            sdc1_pins_b: sdc1@1 {
                allwinner,pins = "PG0", "PG1", "PG2", "PG3", "PG4", "PG5";
                allwinner,function = "io_disabled";
                allwinner,muxsel = <0x07>;
                allwinner,drive = <0x01>;
                allwinner,pull = <0x01>;
                linux,phandle = <0x69>;
                phandle = <0x69>;
            };

            sdc2_pins_b: sdc2@1 {
                allwinner,pins = "PC1", "PC5", "PC6", "PC8", 
					"PC9", "PC10", "PC11", "PC12", 
					"PC13", "PC14", "PC15", "PC16";
                allwinner,function = "io_disabled";
                allwinner,muxsel = <0x07>;
                allwinner,drive = <0x01>;
                allwinner,pull = <0x01>;
                linux,phandle = <0x5f>;
                phandle = <0x5f>;
            };

            daudio0_pins_a: daudio0@0 {
                allwinner,pins = "PB6", "PB3", "PB4", "PB5", "PB7";
                allwinner,function = "pcm0";
                allwinner,muxsel = <0x03>;
                allwinner,drive = <0x01>;
                allwinner,pull = <0x00>;
                linux,phandle = <0x43>;
                phandle = <0x43>;
            };

            daudio0_pins_b: daudio0_sleep@0 {
                allwinner,pins = "PB6", "PB3", "PB4", "PB5", "PB7";
                allwinner,function = "io_disabled";
                allwinner,muxsel = <0x07>;
                allwinner,drive = <0x01>;
                allwinner,pull = <0x00>;
                linux,phandle = <0x44>;
                phandle = <0x44>;
            };

            daudio1_pins_a: daudio1@0 {
                allwinner,pins = "PG10", "PG11", "PG12", "PG13";
                allwinner,function = "pcm1";
                allwinner,muxsel = <0x03>;
                allwinner,drive = <0x01>;
                allwinner,pull = <0x00>;
                linux,phandle = <0x45>;
                phandle = <0x45>;
            };

            daudio1_pins_b: daudio1_sleep@0 {
                allwinner,pins = "PG10", "PG11", "PG12", "PG13";
                allwinner,function = "io_disabled";
                allwinner,muxsel = <0x07>;
                allwinner,drive = <0x01>;
                allwinner,pull = <0x00>;
                linux,phandle = <0x46>;
                phandle = <0x46>;
            };

			aif2_pins_a: aif2@0 {
				allwinner,pins = "PB6", "PB4", "PB5", "PB7";
				allwinner,function = "aif2";
				allwinner,muxsel = <2>;
				allwinner,drive = <1>;
				allwinner,pull = <0>;
			};

            aif2_pins_b: aif2_sleep@0 {
                allwinner,pins = "PB6", "PB4", "PB5", "PB7";
                allwinner,function = "io_disabled";
                allwinner,muxsel = <0x07>;
                allwinner,drive = <0x01>;
                allwinner,pull = <0x00>;
                linux,phandle = <0x3f>;
                phandle = <0x3f>;
            };

            aif3_pins_a: aif3@0 {
                allwinner,pins = "PG10", "PG11", "PG12", "PG13";
                allwinner,function = "aif3";
                allwinner,muxsel = <0x02>;
                allwinner,drive = <0x01>;
                allwinner,pull = <0x00>;
                linux,phandle = <0x3e>;
                phandle = <0x3e>;
            };

            aif3_pins_b: aif3_sleep@0 {
                allwinner,pins = "PG10", "PG11", "PG12", "PG13";
                allwinner,function = "io_disabled";
                allwinner,muxsel = <0x07>;
                allwinner,drive = <0x01>;
                allwinner,pull = <0x00>;
                linux,phandle = <0x40>;
                phandle = <0x40>;
            };

            spdif_pins_a: spdif@0 {
                allwinner,pins = "PH8";
                allwinner,function = "spdif0";
                allwinner,muxsel = <0x02>;
                allwinner,drive = <0x01>;
                allwinner,pull = <0x00>;
                linux,phandle = <0x4a>;
                phandle = <0x4a>;
            };

            spdif_pins_b: spdif_sleep@0 {
                allwinner,pins = "PH8";
                allwinner,function = "io_disabled";
                allwinner,muxsel = <0x07>;
                allwinner,drive = <0x01>;
                allwinner,pull = <0x00>;
                linux,phandle = <0x4b>;
                phandle = <0x4b>;
            };

            csi0_pins_b: csi0_sleep@0 {
                allwinner,pins = "PE0", "PE2", "PE3", "PE4", 
					"PE5", "PE6", "PE7", "PE8", 
					"PE9", "PE10", "PE11", "PE12", "PE13";
                allwinner,pname = "csi0_pck", "csi0_hsync", "csi0_vsync", 
					"csi0_d0", "csi0_d1", "csi0_d2", "csi0_d3", 
					"csi0_d4", "csi0_d5", "csi0_d6", "csi0_d7", 
					"csi0_sck", "csi0_sda";
                allwinner,function = "io_disabled";
                allwinner,muxsel = <0x07>;
                allwinner,drive = <0x01>;
                allwinner,pull = <0x00>;
                allwinner,data = <0x00>;
                linux,phandle = <0x77>;
                phandle = <0x77>;
            };

            scr_pins_a: smartcard@0 {
                allwinner,pins = "PB1", "PB4", "PB5", "PB6", "PB7";
                allwinner,function = "sim0";
                allwinner,muxsel = <0x05>;
                allwinner,drive = <0x01>;
                allwinner,pull = <0x01>;
                linux,phandle = <0x7f>;
                phandle = <0x7f>;
            };

            nand0_pins_c: nand0@2 {
                allwinner,pins = "PC0", "PC1", "PC2", "PC3", 
					"PC4", "PC5", "PC6", "PC7", 
					"PC8", "PC9", "PC10", "PC11", 
					"PC12", "PC13", "PC14", "PC15", 
					"PC16", "PC17", "PC18";
                allwinner,function = "io_disabled";
                allwinner,muxsel = <0x07>;
                allwinner,drive = <0x01>;
                allwinner,pull = <0x00>;
                linux,phandle = <0x83>;
                phandle = <0x83>;
            };

            card0_boot_para_pins_a: card0_boot_para@0 {
                linux,phandle = <0x99>;
                phandle = <0x99>;
                allwinner,pins = "PF0", "PF1", "PF2", "PF3", "PF4", "PF5";
                allwinner,function = "card0_boot_para";
                allwinner,pname = "sdc_d1", "sdc_d0", "sdc_clk", "sdc_cmd", 
					"sdc_d3", "sdc_d2";
                allwinner,muxsel = <0x02>;
                allwinner,pull = <0x01>;
                allwinner,drive = <0x02>;
                allwinner,data = <0xffffffff>;
            };

            card2_boot_para_pins_a: card2_boot_para@0 {
                linux,phandle = <0x9a>;
                phandle = <0x9a>;
                allwinner,pins = "PC1", "PC5", "PC6", "PC8", 
					"PC9", "PC10", "PC11", "PC12", 
					"PC13", "PC14", "PC15", "PC16";
                allwinner,function = "card2_boot_para";
                allwinner,pname = "sdc_ds", "sdc_clk", "sdc_cmd", "sdc_d0", 
					"sdc_d1", "sdc_d2", "sdc_d3", "sdc_d4", 
					"sdc_d5", "sdc_d6", "sdc_d7", "sdc_emmc_rst";
                allwinner,muxsel = <0x03>;
                allwinner,pull = <0x01>;
                allwinner,drive = <0x03>;
                allwinner,data = <0xffffffff>;
            };

            twi_para_pins_a: twi_para@0 {
                linux,phandle = <0x9b>;
                phandle = <0x9b>;
                allwinner,pins = "PH0", "PH1";
                allwinner,function = "twi_para";
                allwinner,pname = "twi_scl", "twi_sda";
                allwinner,muxsel = <0x02>;
                allwinner,pull = <0xffffffff>;
                allwinner,drive = <0xffffffff>;
                allwinner,data = <0xffffffff>;
            };

            uart_para_pins_a: uart_para@0 {
                linux,phandle = <0x9c>;
                phandle = <0x9c>;
                allwinner,pins = "PB8", "PB9";
                allwinner,function = "uart_para";
                allwinner,pname = "uart_debug_tx", "uart_debug_rx";
                allwinner,muxsel = <0x04>;
                allwinner,pull = <0x01>;
                allwinner,drive = <0xffffffff>;
                allwinner,data = <0xffffffff>;
            };

            jtag_para_pins_a: jtag_para@0 {
                linux,phandle = <0x9d>;
                phandle = <0x9d>;
                allwinner,pins = "PB0", "PB1", "PB2", "PB3";
                allwinner,function = "jtag_para";
                allwinner,pname = "jtag_ms", "jtag_ck", "jtag_do", "jtag_di";
                allwinner,muxsel = <0x04>;
                allwinner,pull = <0xffffffff>;
                allwinner,drive = <0xffffffff>;
                allwinner,data = <0xffffffff>;
            };

            gmac0_pins_a: gmac0@0 {
                linux,phandle = <0x9e>;
                phandle = <0x9e>;
                allwinner,pins = "PD18", "PD17", "PD16", "PD15", 
					"PD20", "PD19", "PD11", "PD10", 
					"PD9", "PD8", "PD13", "PD12", 
					"PD21", "PD22", "PD23";
                allwinner,function = "gmac0";
                allwinner,pname = "gmac_txd0", "gmac_txd1", "gmac_txd2", "gmac_txd3", 
					"gmac_txen", "gmac_gtxclk", "gmac_rxd0", "gmac_rxd1", 
					"gmac_rxd2", "gmac_rxd3", "gmac_rxdv", "gmac_rxclk", 
					"gmac_clkin", "gmac_mdc", "gmac_mdio";
                allwinner,muxsel = <0x04>;
                allwinner,pull = <0xffffffff>;
                allwinner,drive = <0xffffffff>;
                allwinner,data = <0xffffffff>;
            };

            twi0_pins_a: twi0@0 {
                linux,phandle = <0x9f>;
                phandle = <0x9f>;
                allwinner,pins = "PH0", "PH1";
                allwinner,function = "twi0";
                allwinner,pname = "twi0_scl", "twi0_sda";
                allwinner,muxsel = <0x02>;
                allwinner,pull = <0xffffffff>;
                allwinner,drive = <0xffffffff>;
                allwinner,data = <0xffffffff>;
            };

            twi1_pins_a: twi1@0 {
                linux,phandle = <0xa0>;
                phandle = <0xa0>;
                allwinner,pins = "PH2", "PH3";
                allwinner,function = "twi1";
                allwinner,pname = "twi1_scl", "twi1_sda";
                allwinner,muxsel = <0x02>;
                allwinner,pull = <0xffffffff>;
                allwinner,drive = <0xffffffff>;
                allwinner,data = <0xffffffff>;
            };

            twi2_pins_a: twi2@0 {
                linux,phandle = <0xa1>;
                phandle = <0xa1>;
                allwinner,pins = "PE14", "PE15";
                allwinner,function = "twi2";
                allwinner,pname = "twi2_scl", "twi2_sda";
                allwinner,muxsel = <0x03>;
                allwinner,pull = <0xffffffff>;
                allwinner,drive = <0xffffffff>;
                allwinner,data = <0xffffffff>;
            };

            uart0_pins_a: uart0@0 {
                linux,phandle = <0xa2>;
                phandle = <0xa2>;
                allwinner,pins = "PB8", "PB9";
                allwinner,function = "uart0";
                allwinner,pname = "uart0_tx", "uart0_rx";
                allwinner,muxsel = <0x04>;
                allwinner,pull = <0x01>;
                allwinner,drive = <0xffffffff>;
                allwinner,data = <0xffffffff>;
            };

            uart1_pins_a: uart1@0 {
                linux,phandle = <0xa3>;
                phandle = <0xa3>;
                allwinner,pins = "PG6", "PG7", "PG8", "PG9";
                allwinner,function = "uart1";
                allwinner,pname = "uart1_tx", "uart1_rx", "uart1_rts", "uart1_cts";
                allwinner,muxsel = <0x02>;
                allwinner,pull = <0x01>;
                allwinner,drive = <0xffffffff>;
                allwinner,data = <0xffffffff>;
            };

            uart2_pins_a: uart2@0 {
                linux,phandle = <0xa4>;
                phandle = <0xa4>;
                allwinner,pins = "PB0", "PB1", "PB2", "PB3";
                allwinner,function = "uart2";
                allwinner,pname = "uart2_tx", "uart2_rx", "uart2_rts", "uart2_cts";
                allwinner,muxsel = <0x02>;
                allwinner,pull = <0x01>;
                allwinner,drive = <0xffffffff>;
                allwinner,data = <0xffffffff>;
            };

            uart3_pins_a: uart3@0 {
                linux,phandle = <0xa5>;
                phandle = <0xa5>;
                allwinner,pins = "PD0", "PD1";
                allwinner,function = "uart3";
                allwinner,pname = "uart3_tx", "uart3_rx";
                allwinner,muxsel = <0x03>;
                allwinner,pull = <0x01>;
                allwinner,drive = <0xffffffff>;
                allwinner,data = <0xffffffff>;
            };

            uart4_pins_a: uart4@0 {
                linux,phandle = <0xa6>;
                phandle = <0xa6>;
                allwinner,pins = "PD2", "PD3", "PD4", "PD5";
                allwinner,function = "uart4";
                allwinner,pname = "uart4_tx", "uart4_rx", "uart4_rts", "uart4_cts";
                allwinner,muxsel = <0x03>;
                allwinner,pull = <0x01>;
                allwinner,drive = <0xffffffff>;
                allwinner,data = <0xffffffff>;
            };

            spi0_pins_a: spi0@0 {
                linux,phandle = <0xa7>;
                phandle = <0xa7>;
                allwinner,pins = "PC3";
                allwinner,function = "spi0";
                allwinner,pname = "spi0_cs0";
                allwinner,muxsel = <0x04>;
                allwinner,pull = <0x01>;
                allwinner,drive = <0xffffffff>;
                allwinner,data = <0xffffffff>;
            };

            spi0_pins_b: spi0@1 {
                linux,phandle = <0xa8>;
                phandle = <0xa8>;
                allwinner,pins = "PC2", "PC0", "PC1";
                allwinner,function = "spi0";
                allwinner,pname = "spi0_sclk", "spi0_mosi", "spi0_miso";
                allwinner,muxsel = <0x04>;
                allwinner,pull = <0xffffffff>;
                allwinner,drive = <0xffffffff>;
                allwinner,data = <0xffffffff>;
            };

            spi1_pins_a: spi1@0 {
                linux,phandle = <0xa9>;
                phandle = <0xa9>;
                allwinner,pins = "PD0";
                allwinner,function = "spi1";
                allwinner,pname = "spi1_cs0";
                allwinner,muxsel = <0x04>;
                allwinner,pull = <0x01>;
                allwinner,drive = <0xffffffff>;
                allwinner,data = <0xffffffff>;
            };

            spi1_pins_b: spi1@1 {
                linux,phandle = <0xaa>;
                phandle = <0xaa>;
                allwinner,pins = "PD1", "PD2", "PD3";
                allwinner,function = "spi1";
                allwinner,pname = "spi1_sclk", "spi1_mosi", "spi1_miso";
                allwinner,muxsel = <0x04>;
                allwinner,pull = <0xffffffff>;
                allwinner,drive = <0xffffffff>;
                allwinner,data = <0xffffffff>;
            };

            nand0_pins_a: nand0@0 {
                linux,phandle = <0xab>;
                phandle = <0xab>;
                allwinner,pins = "PC0", "PC1", "PC2", "PC5", 
					"PC8", "PC9", "PC10", "PC11", 
					"PC12", "PC13", "PC14", "PC15", "PC16";
                allwinner,function = "nand0";
                allwinner,pname = "nand0_we", "nand0_ale", "nand0_cle", "nand0_nre", 
					"nand0_d0", "nand0_d1", "nand0_d2", "nand0_d3", 
					"nand0_d4", "nand0_d5", "nand0_d6", "nand0_d7", "nand0_ndqs";
                allwinner,muxsel = <0x02>;
                allwinner,pull = <0x00>;
                allwinner,drive = <0x01>;
                allwinner,data = <0xffffffff>;
            };

            nand0_pins_b: nand0@1 {
                linux,phandle = <0xac>;
                phandle = <0xac>;
                allwinner,pins = "PC3", "PC4", "PC6", "PC7", "PC17", "PC18";
                allwinner,function = "nand0";
                allwinner,pname = "nand0_ce1", "nand0_ce0", "nand0_rb0", "nand0_rb1", 
					"nand0_ce2", "nand0_ce3";
                allwinner,muxsel = <0x02>;
                allwinner,pull = <0x01>;
                allwinner,drive = <0x01>;
                allwinner,data = <0xffffffff>;
            };

            pwm0_pins_a: pwm0@0 {
                linux,phandle = <0xad>;
                phandle = <0xad>;
                allwinner,pins = "PD22";
                allwinner,function = "pwm0";
                allwinner,pname = "pwm_positive";
                allwinner,muxsel = <0x02>;
                allwinner,pull = <0x00>;
                allwinner,drive = <0xffffffff>;
                allwinner,data = <0xffffffff>;
            };

            pwm0_pins_b: pwm0@1 {
                linux,phandle = <0xae>;
                phandle = <0xae>;
                allwinner,pins = "PD22";
                allwinner,function = "pwm0";
                allwinner,pname = "pwm_positive";
                allwinner,muxsel = <0x07>;
                allwinner,pull = <0x00>;
                allwinner,drive = <0xffffffff>;
                allwinner,data = <0xffffffff>;
            };

            csi0_pins_a: csi0@0 {
                linux,phandle = <0xb1>;
                phandle = <0xb1>;
                allwinner,pins = "PE0", "PE2", "PE3", "PE4", 
					"PE5", "PE6", "PE7", "PE8", 
					"PE9", "PE10", "PE11", "PE12", "PE13";
                allwinner,function = "csi0";
                allwinner,pname = "csi0_pck", "csi0_hsync", "csi0_vsync", "csi0_d0", 
					"csi0_d1", "csi0_d2", "csi0_d3", "csi0_d4", 
					"csi0_d5", "csi0_d6", "csi0_d7", "csi0_sck", "csi0_sda";
                allwinner,muxsel = <0x02>;
                allwinner,pull = <0xffffffff>;
                allwinner,drive = <0xffffffff>;
                allwinner,data = <0xffffffff>;
            };

            sdc0_pins_a: sdc0@0 {
                linux,phandle = <0xb2>;
                phandle = <0xb2>;
                allwinner,pins = "PF0", "PF1", "PF2", "PF3", "PF4", "PF5";
                allwinner,function = "sdc0";
                allwinner,pname = "sdc0_d1", "sdc0_d0", "sdc0_clk", "sdc0_cmd", 
					"sdc0_d3", "sdc0_d2";
                allwinner,muxsel = <0x02>;
                allwinner,pull = <0x01>;
                allwinner,drive = <0x02>;
                allwinner,data = <0xffffffff>;
            };

            sdc1_pins_a: sdc1@0 {
                linux,phandle = <0xb3>;
                phandle = <0xb3>;
                allwinner,pins = "PG0", "PG1", "PG2", "PG3", "PG4", "PG5";
                allwinner,function = "sdc1";
                allwinner,pname = "sdc1_clk", "sdc1_cmd", "sdc1_d0", "sdc1_d1", 
					"sdc1_d2", "sdc1_d3";
                allwinner,muxsel = <0x02>;
                allwinner,pull = <0x01>;
                allwinner,drive = <0x03>;
                allwinner,data = <0xffffffff>;
            };

            sdc2_pins_a: sdc2@0 {
                linux,phandle = <0xb4>;
                phandle = <0xb4>;
                allwinner,pins = "PC1", "PC5", "PC6", "PC8", 
					"PC9", "PC10", "PC11", "PC12", 
					"PC13", "PC14", "PC15", "PC16";
                allwinner,function = "sdc2";
                allwinner,pname = "sdc2_ds", "sdc2_clk", "sdc2_cmd", "sdc2_d0", 
					"sdc2_d1", "sdc2_d2", "sdc2_d3", "sdc2_d4", 
						"sdc2_d5", "sdc2_d6", "sdc2_d7", "sdc2_emmc_rst";
                allwinner,muxsel = <0x03>;
                allwinner,pull = <0x01>;
                allwinner,drive = <0x03>;
                allwinner,data = <0xffffffff>;
            };

            codec_pins_a: codec@0 {
                linux,phandle = <0xb5>;
                phandle = <0xb5>;
                allwinner,pins = "PH7";
                allwinner,function = "codec";
                allwinner,pname = "gpio-spk";
                allwinner,muxsel = <0x02>;
                allwinner,pull = <0x01>;
                allwinner,drive = <0xffffffff>;
                allwinner,data = <0xffffffff>;
            };

            vdevice_pins_a: vdevice@0 {
                linux,phandle = <0xb9>;
                phandle = <0xb9>;
                allwinner,pins = "PB1", "PB2";
                allwinner,function = "vdevice";
                allwinner,pname = "vdevice_0", "vdevice_1";
                allwinner,muxsel = <0x04>;
                allwinner,pull = <0x01>;
                allwinner,drive = <0x02>;
                allwinner,data = <0xffffffff>;
            };

            w1_pin_pins_a: w1_pin@0 {
                linux,phandle = <0xba>;
                phandle = <0xba>;
                allwinner,pins = "PC8";
                allwinner,function = "gpio_in";
                allwinner,pname = "w1";
                allwinner,muxsel = <0x0>;
                allwinner,pull = <0x1>;
                allwinner,drive = <0x0>;
                allwinner,data = <0xffffffff>;
            };
        };

        axp_pio: pinctrl@0 {
            compatible = "allwinner,axp-pinctrl";
            gpio-controller;
            #size-cells = <0x00>;
            #gpio-cells = <0x06>;
            device_type = "axp_pio";
            linux,phandle = <0x31>;
            phandle = <0x31>;
        };

        dma0: dma-controller@01c02000 {
            compatible = "allwinner,sun50i-dma";
            reg = <0x00 0x01c02000 0x00 0x1000>;
            interrupts = <0x00 0x32 0x04>;
            clocks = <&clk_dma>;
            #dma-cells = <0x01>;
        };

        mbus0: mbus-controller@01c62000 {
            compatible = "allwinner,sun50i-mbus";
            reg = <0x00 0x01c62000 0x00 0x0110>;
            #mbus-cells = <0x01>;
        };

        arisc {
            compatible = "allwinner,sunxi-arisc";
            #address-cells = <0x02>;
            #size-cells = <0x02>;
            clocks = <&clk_losc>, <&clk_iosc>, <&clk_hosc>, <&clk_pll_periph0>;
            clock-names = "losc", "iosc", "hosc", "pll_periph0";
            powchk_used = <0x00>;
            power_reg = <0x02309621>;
            system_power = <0x32>;
        };

        arisc_space {
            compatible = "allwinner,arisc_space";
            space1 = <0x00040000 0x00 0x00014000>;
            space2 = <0x40100000 0x00018000 0x4000>;
            space3 = <0x40104000 0x00 0x1000>;
            space4 = <0x40105000 0x00 0x1000>;
        };

        standby_space {
            compatible = "allwinner,standby_space";
            space1 = <0x41020000 0x00 0x0800>;
        };

        msgbox: msgbox@1c17000 {
            compatible = "allwinner,msgbox";
            clocks = <&clk_msgbox>;
            clock-names = "clk_msgbox";
            reg = <0x00 0x01c17000 0x00 0x1000>;
            interrupts = <0x00 0x31 0x01>;
            status = "okay";
        };

        hwspinlock: hwspinlock@1c18000 {
            compatible = "allwinner,sunxi-hwspinlock";
            clocks = <&clk_hwspinlock_rst>, <&clk_hwspinlock_bus>;
            clock-names = "clk_hwspinlock_rst", "clk_hwspinlock_bus";
            reg = <0x00 0x01c18000 0x00 0x1000>;
            status = "okay";
            num-locks = <0x08>;
        };

        s_cir0: s_cir@1f02000 {
            compatible = "allwinner,s_cir";
            reg = <0x00 0x01f02000 0x00 0x0400>;
            interrupts = <0x00 0x25 0x04>;
            pinctrl-names = "default";
            pinctrl-0 = <&s_cir0_pins_a>;
            clocks = <&clk_hosc>, <&clk_cpurcir>;
            supply = "vcc-pl";
            ir_power_key_code = <0x4d>;
            ir_addr_code = <0x4040>;
            status = "okay";
            device_type = "s_cir0";
        };

        s_uart0: s_uart@1f02800 {
            compatible = "allwinner,s_uart";
            reg = <0x00 0x01f02800 0x00 0x0400>;
            interrupts = <0x00 0x26 0x04>;
            pinctrl-names = "default";
            status = "okay";
            device_type = "s_uart0";
            pinctrl-0 = <&s_uart0_pins_a>;
        };

        s_twi0: s_twi@0x01f02400 {
            #address-cells = <0x01>;
            #size-cells = <0x00>;
            compatible = "allwinner,sun50i-twi";
            device_type = "s_twi0";
            reg = <0x00 0x01f02400 0x00 0x0400>;
            interrupts = <0x00 0x06 0x04>;
            clocks = <&clk_twi0>;
            clock-frequency = <0x00061a80>;
            pinctrl-names = "default", "sleep";
            pinctrl-0 = <&s_twi0_pins_a>;
            pinctrl-1 = <&s_twi0_pins_b>;
            status = "okay";
	    	pcm5122: pcm5122@4c {
	 			compatible = "ti,pcm5122";
	    		reg = <0x4c>;
    	    };
        };

        s_rsb0: s_rsb@1f03400 {
            compatible = "allwinner,s_rsb";
            reg = <0x00 0x01f03400 0x00 0x0400>;
            interrupts = <0x00 0x27 0x04>;
            pinctrl-names = "default";
            status = "okay";
            device_type = "s_rsb0";
            pinctrl-0 = <&s_rsb0_pins_a>;
        };

        s_jtag0: s_jtag0 {
            compatible = "allwinner,s_jtag";
            pinctrl-names = "default";
            status = "disabled";
            device_type = "s_jtag0";
            pinctrl-0 = <&s_jtag0_pins_a>;
        };

        soc_timer0: timer@1c20c00 {
            compatible = "allwinner,sunxi-timer";
            device_type = "timer";
            reg = <0x00 0x01c20c00 0x00 0x90>;
            interrupts = <0x00 0x12 0x01>;
            clock-frequency = <0x016e3600>;
            timer-prescale = <0x10>;
        };

        rtc: rtc@01f00000 {
            compatible = "allwinner,sun50i-rtc";
            device_type = "rtc";
            reg = <0x00 0x01f00000 0x00 0x0218>;
            interrupts = <0x00 0x28 0x04>;
            gpr_offset = <0x0100>;
            gpr_len = <0x04>;
        };

        ve@01c0e000 {
            compatible = "allwinner,sunxi-cedar-ve";
            reg = <0x00 0x01c0e000 0x00 
				0x1000 0x00 0x01c00000 
				0x00 0x10 0x00 
				0x01c20000 0x00 0x0800>;
            interrupts = <0x00 0x3a 0x04>;
            clocks = <&clk_pll_ve>, <&clk_ve>;
        };

        uart0: uart@01c28000 {
            compatible = "allwinner,sun50i-uart";
            device_type = "uart0";
            reg = <0x00 0x01c28000 0x00 0x0400>;
            interrupts = <0x00 0x00 0x04>;
            clocks = <&clk_uart0>;
            pinctrl-names = "default", "sleep";
            pinctrl-0 = <&uart0_pins_a>;
            pinctrl-1 = <&uart0_pins_b>;
            uart0_port = <0x00>;
            uart0_type = <0x02>;
            status = "okay";
        };

        uart1: uart@01c28400 {
            compatible = "allwinner,sun50i-uart";
            device_type = "uart1";
            reg = <0x00 0x01c28400 0x00 0x0400>;
            interrupts = <0x00 0x01 0x04>;
            clocks = <&clk_uart1>;
            pinctrl-names = "default", "sleep";
            pinctrl-0 = <&uart1_pins_a>;
            pinctrl-1 = <&uart1_pins_b>;
            uart1_port = <0x01>;
            uart1_type = <0x04>;
            status = "okay";
        };

        uart2: uart@01c28800 {
            compatible = "allwinner,sun50i-uart";
            device_type = "uart2";
            reg = <0x00 0x01c28800 0x00 0x0400>;
            interrupts = <0x00 0x02 0x04>;
            clocks = <&clk_uart2>;
            pinctrl-names = "default", "sleep";
            pinctrl-0 = <&uart2_pins_a>;
            pinctrl-1 = <&uart2_pins_b>;
            uart2_port = <0x02>;
            uart2_type = <0x04>;
            status = "disabled";
        };

        uart3: uart@01c28c00 {
            compatible = "allwinner,sun50i-uart";
            device_type = "uart3";
            reg = <0x00 0x01c28c00 0x00 0x0400>;
            interrupts = <0x00 0x03 0x04>;
            clocks = <&clk_uart3>;
            pinctrl-names = "default", "sleep";
            pinctrl-0 = <&uart3_pins_a>;
            pinctrl-1 = <&uart3_pins_b>;
            uart3_port = <0x03>;
            uart3_type = <0x04>;
            status = "okay";
        };

        uart4: uart@01c29000 {
            compatible = "allwinner,sun50i-uart";
            device_type = "uart4";
            reg = <0x00 0x01c29000 0x00 0x0400>;
            interrupts = <0x00 0x04 0x04>;
            clocks = <&clk_uart4>;
            pinctrl-names = "default", "sleep";
            pinctrl-0 = <&uart4_pins_a>;
            pinctrl-1 = <&uart4_pins_b>;
            uart4_port = <0x04>;
            uart4_type = <0x04>;
            status = "okay";
        };

        twi0: twi@0x01c2ac00 {
            #address-cells = <0x01>;
            #size-cells = <0x00>;
            compatible = "allwinner,sun50i-twi";
            device_type = "twi0";
            reg = <0x00 0x01c2ac00 0x00 0x0400>;
            interrupts = <0x00 0x06 0x04>;
            clocks = <&clk_twi0>;
            clock-frequency = <0x00061a80>;
            pinctrl-names = "default", "sleep";
            pinctrl-0 = <&twi0_pins_a>;
            pinctrl-1 = <&twi0_pins_b>;
            status = "disabled";
        };

        twi1: twi@0x01c2b000 {
            #address-cells = <0x01>;
            #size-cells = <0x00>;
            compatible = "allwinner,sun50i-twi";
            device_type = "twi1";
            reg = <0x00 0x01c2b000 0x00 0x0400>;
            interrupts = <0x00 0x07 0x04>;
            clocks = <&clk_twi1>;
            clock-frequency = <0x00030d40>;
            pinctrl-names = "default", "sleep";
            pinctrl-0 = <&twi1_pins_a>;
            pinctrl-1 = <&twi1_pins_b>;
            status = "disabled";
        };

        twi2: twi@0x01c2b400 {
            #address-cells = <0x01>;
            #size-cells = <0x00>;
            compatible = "allwinner,sun50i-twi";
            device_type = "twi2";
            reg = <0x00 0x01c2b400 0x00 0x0400>;
            interrupts = <0x00 0x08 0x04>;
            clocks = <&clk_twi2>;
            clock-frequency = <0x00030d40>;
            pinctrl-names = "default", "sleep";
            pinctrl-0 = <&twi2_pins_a>;
            pinctrl-1 = <&twi2_pins_b>;
            status = "disabled";
        };

        usbc0: usbc0@0 {
            device_type = "usbc0";
            compatible = "allwinner,sunxi-otg-manager";
            usb_port_type = <0x01>;
            usb_detect_type = <0x00>;
            usb_host_init_state = <0x01>;
            usb_regulator_io = "nocare";
            usb_wakeup_suspend = <0x01>;
            usb_luns = <0x03>;
            usb_serial_unique = <0x01>;
            usb_serial_number = "20080411";
            rndis_wceis = <0x01>;
            status = "okay";
            usb_id_gpio;
            usb_det_vbus_gpio;
            usb_drv_vbus_gpio;
        };

        udc: udc-controller@0x01c19000 {
            compatible = "allwinner,sunxi-udc";
            reg = <0x00 0x01c19000 0x00 0x1000 0x00 0x01c00000 0x00 0x0100>;
            interrupts = <0x00 0x47 0x04>;
            clocks = <&clk_usbphy0>, <&clk_usbotg>;
            status = "okay";
        };

        ehci0: ehci0-controller@0x01c1a000 {
            compatible = "allwinner,sunxi-ehci0";
            reg = <0x00 0x01c1a000 0x00 0x0fff 
				0x00 0x01c00000 0x00 0x0100 
				0x00 0x01c19000 0x00 0x1000>;
            interrupts = <0x00 0x48 0x04>;
            clocks = <&clk_usbphy0>, <&clk_usbehci0>;
            hci_ctrl_no = <0x00>;
            status = "okay";
        };

        ohci0: ohci0-controller@0x01c1a400 {
            compatible = "allwinner,sunxi-ohci0";
            reg = <0x00 0x01c1a000 0x00 0x0fff 
				0x00 0x01c00000 0x00 0x0100 
				0x00 0x01c19000 0x00 0x1000>;
            interrupts = <0x00 0x49 0x04>;
            clocks = <&clk_usbphy0>, <&clk_usbohci0>;
            hci_ctrl_no = <0x00>;
            status = "okay";
        };

        usbc1: usbc1@0 {
            device_type = "usbc1";
            usb_host_init_state = <0x01>;
            usb_regulator_io = "nocare";
            usb_wakeup_suspend = <0x01>;
            usb_hsic_used = <0x00>;
            usb_hsic_regulator_io = "vcc-hsic-12";
            usb_hsic_ctrl = <0x00>;
            usb_hsic_usb3503_flag = <0x00>;
            status = "okay";
            usb_port_type = <0x01>;
            usb_detect_type = <0x00>;
            usb_drv_vbus_gpio;
            usb_hsic_rdy_gpio;
            usb_hsic_hub_connect_gpio;
            usb_hsic_int_n_gpio;
            usb_hsic_reset_n_gpio;
        };

        ehci1: ehci1-controller@0x01c1b000 {
            compatible = "allwinner,sunxi-ehci1";
            reg = <0x00 0x01c1b000 0x00	0x0fff 
				0x00 0x01c00000 0x00 0x0100 
				0x00 0x01c19000 0x00 0x1000>;
            interrupts = <0x00 0x4a 0x04>;
			clocks = <&clk_usbphy1>, <&clk_usbehci1>, <&clk_usbhsic>, 
				<&clk_usbhsic12m>, <&clk_pll_hsic>;
            hci_ctrl_no = <0x01>;
            status = "okay";
        };
		
        ohci1: ohci1-controller@0x01c1b400 {
            compatible = "allwinner,sunxi-ohci1";
            reg = <0x00 0x01c1b000 0x00 0x0fff 
				0x00 0x01c00000 0x00 0x0100 
				0x00 0x01c19000 0x00 0x1000>;
            interrupts = <0x00 0x4b 0x04>;
            clocks = <&clk_usbphy1>, <&clk_usbohci1>;
            hci_ctrl_no = <0x01>;
            status = "okay";
        };

        codec: codec@0x01c22c00 {
            compatible = "allwinner,sunxi-internal-codec";
            reg = <0x00 0x01c22c00 0x00 0x0478 
				0x00 0x01f015c0 0x00 0x00>;
            clocks = <0x3c>;
            pinctrl-names = "aif2-default", "aif3-default", "aif2-sleep", "aif3-sleep";
            pinctrl-0 = <&aif2_pins_a>;
            pinctrl-1 = <&aif3_pins_a>;
            pinctrl-2 = <&aif2_pins_b>;
            pinctrl-3 = <&aif3_pins_b>;
            gpio-spk = <&pio 0x07 0x07 0x01 0x01 0x01 0x01>;
            headphonevol = <0x3b>;
            spkervol = <0x1a>;
            earpiecevol = <0x1e>;
            maingain = <0x04>;
            headsetmicgain = <0x04>;
            adcagc_cfg = <0x00>;
            adcdrc_cfg = <0x00>;
            adchpf_cfg = <0x00>;
            dacdrc_cfg = <0x00>;
            dachpf_cfg = <0x00>;
            aif1_lrlk_div = <0x40>;
            aif2_lrlk_div = <0x40>;
            aif2config = <0x00>;
            aif3config = <0x00>;
            pa_sleep_time = <0x015e>;
            dac_digital_vol = <0xa0a0>;
            status = "okay";
            linux,phandle = <0x4d>;
            phandle = <0x4d>;
            device_type = "codec";
        };

        i2s: i2s0-controller@0x01c22c00 {
            compatible = "allwinner,sunxi-internal-i2s";
            reg = <0x00 0x01c22c00 0x00 0x0478>;
            clocks = <&clk_pll_audio>, <&clk_adda>;
            status = "okay";
            linux,phandle = <0x4c>;
            phandle = <0x4c>;
            device_type = "i2s";
        };

        daudio0: daudio@0x01c22000 {
            compatible = "allwinner,sunxi-daudio";
            reg = <0x00 0x01c22000 0x00 0x58>;
            clocks = <&clk_pll_audio>, <&clk_i2s0>;
            pinctrl-names = "default", "sleep";
            pinctrl-0 = <&daudio0_pins_a>;
            pinctrl-1 = <&daudio0_pins_b>;
            pcm_lrck_period = <0x20>;
            pcm_lrckr_period = <0x01>;
            slot_width_select = <0x20>;
            pcm_lsb_first = <0x00>;
            tx_data_mode = <0x00>;
            rx_data_mode = <0x00>;
            daudio_master = <0x04>;
            audio_format = <0x01>;
            signal_inversion = <0x01>;
            frametype = <0x00>;
            tdm_config = <0x01>;
            tdm_num = <0x00>;
            status = "okay";
            linux,phandle = <0x4e>;
            phandle = <0x4e>;
            device_type = "daudio0";
        };

        daudio1: daudio@0x01c22400 {
            compatible = "allwinner,sunxi-daudio";
            reg = <0x00 0x01c22400 0x00 0x58>;
            pinctrl-names = "default", "sleep";
            pinctrl-0 = <&daudio1_pins_a>;
            pinctrl-1 = <&daudio1_pins_b>;
            clocks = <&clk_pll_audio>, <&clk_i2s1>;
            pcm_lrck_period = <0x20>;
            pcm_lrckr_period = <0x01>;
            slot_width_select = <0x20>;
            pcm_lsb_first = <0x00>;
            tx_data_mode = <0x00>;
            rx_data_mode = <0x00>;
            daudio_master = <0x04>;
            audio_format = <0x01>;
            signal_inversion = <0x01>;
            frametype = <0x00>;
            tdm_config = <0x01>;
            tdm_num = <0x01>;
            status = "disabled";
            linux,phandle = <0x4f>;
            phandle = <0x4f>;
            device_type = "daudio1";
        };

        daudio2: daudio@0x01c22800 {
            compatible = "allwinner,sunxi-tdmhdmi";
            reg = <0x00 0x01c22800 0x00 0x58>;
            clocks = <&clk_pll_audio>, <&clk_i2s2>;
            status = "okay";
            linux,phandle = <0x50>;
            phandle = <0x50>;
            device_type = "daudio2";
        };

        spdif: spdif-controller@0x01c21000 {
            compatible = "allwinner,sunxi-spdif";
            reg = <0x00 0x01c21000 0x00 0x38>;
            clocks = <&clk_pll_audio>, <&clk_spdif>;
            pinctrl-names = "default", "sleep";
            pinctrl-0 = <&spdif_pins_a>;
            pinctrl-1 = <&spdif_pins_b>;
            status = "disabled";
            linux,phandle = <0x51>;
            phandle = <0x51>;
            device_type = "spdif";
        };

        sndcodec: sound@0 {
            compatible = "allwinner,sunxi-codec-machine";
            interrupts = <0x00 0x1c 0x04>;
            sunxi,i2s-controller = <&i2s>;
            sunxi,audio-codec = <&codec>;
            aif2fmt = <0x03>;
            aif3fmt = <0x03>;
            aif2master = <0x01>;
            hp_detect_case = <0x01>;
            status = "okay";
            device_type = "sndcodec";
        };

        snddaudio0: sound@1 {
            compatible = "allwinner,sunxi-daudio0-machine";
            sunxi,daudio0-controller = <&daudio0>;
            status = "disabled";
            device_type = "snddaudio0";
        };

        snddaudio1: sound@2 {
            compatible = "allwinner,sunxi-daudio1-machine";
            sunxi,daudio1-controller = <&daudio1>;
            status = "disabled";
            device_type = "snddaudio1";
        };

        sndhdmi: sound@3 {
            compatible = "allwinner,sunxi-hdmi-machine";
            sunxi,hdmi-controller = <&daudio2>;
            status = "okay";
            device_type = "sndhdmi";
        };

        sndspdif: sound@4 {
            compatible = "allwinner,sunxi-spdif-machine";
            sunxi,spdif-controller = <&spdif>;
            status = "disabled";
            device_type = "sndspdif";
        };

		sndpcm5122: sound@5 {
            compatible = "allwinner,sunxi-pcm5122-machine";
            sunxi,pcm5122-controller = <&daudio0>;
            status = "okay";
            device_type = "sndpcm5122";
		};

        spi0: spi@01c68000 {
            #address-cells = <0x01>;
            #size-cells = <0x00>;
            compatible = "allwinner,sun50i-spi";
            device_type = "spi0";
            reg = <0x00 0x01c68000 0x00 0x1000>;
            interrupts = <0x00 0x41 0x04>;
            clocks = <&clk_pll_periph0>, <&clk_spi0>;
            clock-frequency = <0x05f5e100>;
            pinctrl-names = "default", "sleep";
            pinctrl-0 = <&spi0_pins_a &spi0_pins_b>;
            pinctrl-1 = <&spi0_pins_c>;
            spi0_cs_number = <0x01>;
            spi0_cs_bitmap = <0x01>;
            status = "disabled";
        };

        spi1: spi@01c69000 {
            #address-cells = <0x01>;
            #size-cells = <0x00>;
            compatible = "allwinner,sun50i-spi";
            device_type = "spi1";
            reg = <0x00 0x01c69000 0x00 0x1000>;
            interrupts = <0x00 0x42 0x04>;
            clocks = <&clk_pll_periph0>, <&clk_spi1>;
            clock-frequency = <0x05f5e100>;
            pinctrl-names = "default", "sleep";
            pinctrl-0 = <&spi1_pins_a &spi1_pins_b>;
            pinctrl-1 = <&spi1_pins_c>;
            spi1_cs_number = <0x01>;
            spi1_cs_bitmap = <0x01>;
            status = "disabled";
        };

        sdc2: sdmmc@01C11000 {
            compatible = "allwinner,sun50i-sdmmc2";
            device_type = "sdc2";
            reg = <0x00 0x01c11000 0x00 0x1000>;
            interrupts = <0x00 0x3e 0x0104>;
			clocks = <&clk_hosc>,<&clk_pll_periph1x2>,
				<&clk_sdmmc2_mod>,<&clk_sdmmc2_bus>,<&clk_sdmmc2_rst>;
            clock-names = "osc24m", "pll_periph", "mmc", "ahb", "rst";
            pinctrl-names = "default", "sleep";
            pinctrl-0 = <&sdc2_pins_a>;
            pinctrl-1 = <&sdc2_pins_b>;
            bus-width = <0x08>;
            max-frequency = <0x05f5e100>;
            sdc_tm4_sm0_freq0 = <0x00>;
            sdc_tm4_sm0_freq1 = <0x00>;
            sdc_tm4_sm1_freq0 = <0x00>;
            sdc_tm4_sm1_freq1 = <0x00>;
            sdc_tm4_sm2_freq0 = <0x00>;
            sdc_tm4_sm2_freq1 = <0x00>;
            sdc_tm4_sm3_freq0 = <0x05000000>;
            sdc_tm4_sm3_freq1 = <0x0405>;
            sdc_tm4_sm4_freq0 = <0x00050000>;
            sdc_tm4_sm4_freq1 = <0x0408>;
            status = "disabled";
            non-removable;
            cd-gpios;
            sunxi-power-save-mode;
            sunxi-dis-signal-vol-sw;
            mmc-ddr-1_8v;
            mmc-hs200-1_8v;
            mmc-hs400-1_8v;
            vmmc = "vcc-emmc";
            vqmmc = "vcc-lpddr";
            vdmmc = "none";
        };

        sdc0: sdmmc@01c0f000 {
            compatible = "allwinner,sun50i-sdmmc0";
            device_type = "sdc0";
            reg = <0x00 0x01c0f000 0x00 0x1000>;
            interrupts = <0x00 0x3c 0x0104>;
			clocks = <&clk_hosc>,<&clk_pll_periph1x2>,<&clk_sdmmc0_mod>,
				<&clk_sdmmc0_bus>,<&clk_sdmmc0_rst>;
            clock-names = "osc24m", "pll_periph", "mmc", "ahb", "rst";
            pinctrl-names = "default", "sleep";
            pinctrl-0 = <&sdc0_pins_a>;
            pinctrl-1 = <&sdc0_pins_b>;
            max-frequency = <0x02faf080>;
            bus-width = <0x04>;
            broken-cd;
            status = "okay";
            cd-gpios = <&pio 0x05 0x06 0x00 0x01 0x02 0xffffffff>;
            sunxi-power-save-mode;
            vmmc = "none";
            vqmmc = "none";
            vdmmc = "vcc-sdc";
        };

        sdc1: sdmmc@1C10000 {
            compatible = "allwinner,sun50i-sdmmc1";
            device_type = "sdc1";
            reg = <0x00 0x01c10000 0x00 0x1000>;
            interrupts = <0x00 0x3d 0x0104>;
			clocks = <&clk_hosc>,<&clk_pll_periph1x2>,<&clk_sdmmc1_mod>,
				<&clk_sdmmc1_bus>,<&clk_sdmmc1_rst>;
            clock-names = "osc24m", "pll_periph", "mmc", "ahb", "rst";
            pinctrl-names = "default", "sleep";
            pinctrl-0 = <&sdc1_pins_a>;
            pinctrl-1 = <&sdc1_pins_b>;
            max-frequency = <0x08f0d180>;
            bus-width = <0x04>;
            sunxi-dly-52M-ddr4 = <0x01 0x00 0x00 0x00 0x02>;
            sunxi-dly-104M = <0x01 0x00 0x00 0x00 0x01>;
            sunxi-dly-208M = <0x01 0x00 0x00 0x00 0x01>;
            status = "okay";
            sd-uhs-sdr50;
            sd-uhs-ddr50;
            sd-uhs-sdr104;
            cap-sdio-irq;
            keep-power-in-suspend;
            ignore-pm-notify;
        };

        disp: disp@01000000 {
            compatible = "allwinner,sun50i-disp";
            reg = <0x00 0x01000000 
				0x00 0x00300000 
				0x00 0x01c0c000 
				0x00 0x17fc 
				0x00 0x01ca0000 
				0x00 0x10fc>;
            interrupts = <0x00 0x56 0x0104 
				0x00 0x57 0x0104 
				0x00 0x59 0x0104>;
			clocks = <&clk_de>,<&clk_tcon0>,<&clk_lvds>,<&clk_mipidsi>,<&clk_tcon1>;
            status = "okay";
            device_type = "disp";
            disp_init_enable = <0x01>;
            disp_mode = <0x00>;
            screen0_output_type = <0x03>;
            screen0_output_mode = <0x0a>;
            screen1_output_type = <0x03>;
            screen1_output_mode = <0x0a>;
            fb0_format = <0x00>;
            fb0_width = <0x00>;
            fb0_height = <0x00>;
            fb1_format = <0x00>;
            fb1_width = <0x00>;
            fb1_height = <0x00>;
        };

        lcd0: lcd0@01c0c000 {
            compatible = "allwinner,sunxi-lcd0";
            pinctrl-names = "active", "sleep";
            status = "okay";
            device_type = "lcd0";
            lcd_used = <0x00>;
            lcd_driver_name = "mb709_mipi";
            lcd_backlight = <0x32>;
            lcd_if = <0x04>;
            lcd_x = <0x0400>;
            lcd_y = <0x0258>;
            lcd_width = <0x00>;
            lcd_height = <0x00>;
            lcd_dclk_freq = <0x37>;
            lcd_pwm_used = <0x01>;
            lcd_pwm_ch = <0x10>;
            lcd_pwm_freq = <0xc350>;
            lcd_pwm_pol = <0x01>;
            lcd_pwm_max_limit = <0xfa>;
            lcd_hbp = <0x78>;
            lcd_ht = <0x0604>;
            lcd_hspw = <0x14>;
            lcd_vbp = <0x17>;
            lcd_vt = <0x027b>;
            lcd_vspw = <0x02>;
            lcd_dsi_if = <0x02>;
            lcd_dsi_lane = <0x04>;
            lcd_dsi_format = <0x00>;
            lcd_dsi_eotp = <0x00>;
            lcd_dsi_vc = <0x00>;
            lcd_dsi_te = <0x00>;
            lcd_frm = <0x00>;
            lcd_gamma_en = <0x00>;
            lcd_bright_curve_en = <0x00>;
            lcd_cmap_en = <0x00>;
            lcd_bl_en = <&pio 0x07 0x0a 0x01 0x00 0xffffffff 0x01>;
            lcd_bl_en_power = "none";
            lcd_power = "vcc-mipi";
            lcd_fix_power = "vcc-dsi-33";
            lcd_gpio_0 = <&pio 0x03 0x18 0x01 0x00 0xffffffff 0x01>;
        };

        hdmi: hdmi@01ee0000 {
            compatible = "allwinner,sunxi-hdmi";
            reg = <0x00 0x01ee0000 0x00 0x00020000>;
            clocks = <&clk_hdmi>, <&clk_hdmi_slow>;
            device_type = "hdmi";
            status = "okay";
            hdmi_power = "vcc-hdmi-33";
            hdmi_hdcp_enable = <0x00>;
            hdmi_cts_compatibility = <0x00>;
        };

        soc_tr: tr@01000000 {
            compatible = "allwinner,sun50i-tr";
            reg = <0x00 0x01000000 0x00 0x000200bc>;
            interrupts = <0x00 0x60 0x0104>;
            clocks = <&clk_de>;
            status = "okay";
        };

        pwm: pwm@01c21400 {
            compatible = "allwinner,sunxi-pwm";
            reg = <0x00 0x01c21400 0x00 0x3c>;
            pwm-number = <0x01>;
            pwm-base = <0x00>;
            pwms = <&pwm0>;
        };

        pwm0: pwm0@01c21400 {
            compatible = "allwinner,sunxi-pwm0";
            pinctrl-names = "active", "sleep";
            reg_base = <0x01c21400>;
            reg_busy_offset = <0x00>;
            reg_busy_shift = <0x1c>;
            reg_enable_offset = <0x00>;
            reg_enable_shift = <0x04>;
            reg_clk_gating_offset = <0x00>;
            reg_clk_gating_shift = <0x06>;
            reg_bypass_offset = <0x00>;
            reg_bypass_shift = <0x09>;
            reg_pulse_start_offset = <0x00>;
            reg_pulse_start_shift = <0x08>;
            reg_mode_offset = <0x00>;
            reg_mode_shift = <0x07>;
            reg_polarity_offset = <0x00>;
            reg_polarity_shift = <0x05>;
            reg_period_offset = <0x04>;
            reg_period_shift = <0x10>;
            reg_period_width = <0x10>;
            reg_active_offset = <0x04>;
            reg_active_shift = <0x00>;
            reg_active_width = <0x10>;
            reg_prescal_offset = <0x00>;
            reg_prescal_shift = <0x00>;
            reg_prescal_width = <0x04>;
            linux,phandle = <0x71>;
            phandle = <0x71>;
            device_type = "pwm0";
            pwm_used = <0x00>;
            pinctrl-0 = <0xad>;
            pinctrl-1 = <0xae>;
        };

        s_pwm: s_pwm@1f03800 {
            compatible = "allwinner,sunxi-s_pwm";
            reg = <0x00 0x01f03800 0x00 0x3c>;
            pwm-number = <0x01>;
            pwm-base = <0x10>;
            pwms = <&spwm0>;
        };

        spwm0: spwm0@0x01f03800 {
            compatible = "allwinner,sunxi-pwm16";
            pinctrl-names = "active", "sleep";
            reg_base = <0x01f03800>;
            reg_busy_offset = <0x00>;
            reg_busy_shift = <0x1c>;
            reg_enable_offset = <0x00>;
            reg_enable_shift = <0x04>;
            reg_clk_gating_offset = <0x00>;
            reg_clk_gating_shift = <0x06>;
            reg_bypass_offset = <0x00>;
            reg_bypass_shift = <0x09>;
            reg_pulse_start_offset = <0x00>;
            reg_pulse_start_shift = <0x08>;
            reg_mode_offset = <0x00>;
            reg_mode_shift = <0x07>;
            reg_polarity_offset = <0x00>;
            reg_polarity_shift = <0x05>;
            reg_period_offset = <0x04>;
            reg_period_shift = <0x10>;
            reg_period_width = <0x10>;
            reg_active_offset = <0x04>;
            reg_active_shift = <0x00>;
            reg_active_width = <0x10>;
            reg_prescal_offset = <0x00>;
            reg_prescal_shift = <0x00>;
            reg_prescal_width = <0x04>;
            linux,phandle = <0x72>;
            phandle = <0x72>;
            device_type = "spwm0";
            s_pwm_used = <0x01>;
            pinctrl-0 = <0xaf>;
            pinctrl-1 = <0xb0>;
        };

        boot_disp: boot_disp {
            compatible = "allwinner,boot_disp";
            device_type = "boot_disp";
            output_disp = <0x00>;
            output_type = <0x03>;
            output_mode = <0x0a>;
        };

        csi_cci0: cci@0x01cb3000 {
            compatible = "allwinner,sunxi-csi_cci";
            reg = <0x00 0x01cb3000 0x00 0x1000>;
            interrupts = <0x00 0x55 0x04>;
            status = "okay";
        };

        csi_res0: csi_res@0x01cb0000 {
            compatible = "allwinner,sunxi-csi";
            reg = <0x00 0x01cb0000 0x00 0x1000>;
            status = "okay";
        };

        csi0: vfe@0 {
            device_type = "csi0";
            compatible = "allwinner,sunxi-vfe";
            interrupts = <0x00 0x54 0x04>;
			clocks = <&clk_csi_s>, <&clk_csi_m>,<&clk_csi_misc>,
				<&clk_pll_periph0>,<&clk_hosc>,<&clk_pll_periph1>;
            pinctrl-names = "default", "sleep";
            pinctrl-0 = <&csi0_pins_a>;
            pinctrl-1 = <&csi0_pins_b>;
            csi0_sensor_list = <0x01>;
            status = "okay";
            csi0_mck = <&pio 0x04 0x01 0x00 0x00 0x01 0x00>;
            csi_dev0: dev@0 {
                csi0_dev0_mname = "s5k4ec";
                csi0_dev0_twi_addr = <0x5a>;
                csi0_dev0_pos = "rear";
                csi0_dev0_isp_used = <0x01>;
                csi0_dev0_fmt = <0x00>;
                csi0_dev0_stby_mode = <0x01>;
                csi0_dev0_vflip = <0x00>;
                csi0_dev0_hflip = <0x00>;
                csi0_dev0_iovdd = "iovdd-csi";
                csi0_dev0_iovdd_vol = <0x002ab980>;
                csi0_dev0_avdd = "avdd-csi";
                csi0_dev0_avdd_vol = <0x002ab980>;
                csi0_dev0_dvdd = "dvdd-csi-18";
                csi0_dev0_dvdd_vol = <0x0016e360>;
                csi0_dev0_flash_used = <0x00>;
                csi0_dev0_flash_type = <0x02>;
                csi0_dev0_flvdd = "vdd-csi-led";
                csi0_dev0_flvdd_vol = <0x00325aa0>;
                csi0_dev0_act_used = <0x00>;
                csi0_dev0_act_name = "ad5820_act";
                csi0_dev0_act_slave = <0x18>;
                status = "disabled";
                device_type = "csi0_dev0";
                csi0_dev0_afvdd;
                csi0_dev0_afvdd_vol;
                csi0_dev0_power_en;
                csi0_dev0_reset = <&pio 0x04 0x10 0x00 0x00 0x01 0x00>;
                csi0_dev0_pwdn = <&pio 0x04 0x11 0x00 0x00 0x01 0x00>;
                csi0_dev0_flash_en;
                csi0_dev0_flash_mode;
                csi0_dev0_af_pwdn;
            };

            csi_dev1: dev@1 {
                csi0_dev1_mname = "gc2145";
                csi0_dev1_twi_addr = <0x78>;
                csi0_dev1_pos = "front";
                csi0_dev1_isp_used = <0x01>;
                csi0_dev1_fmt = <0x00>;
                csi0_dev1_stby_mode = <0x01>;
                csi0_dev1_vflip = <0x00>;
                csi0_dev1_hflip = <0x00>;
                csi0_dev1_iovdd = "iovdd-csi";
                csi0_dev1_iovdd_vol = <0x002ab980>;
                csi0_dev1_avdd = "avdd-csi";
                csi0_dev1_avdd_vol = <0x002ab980>;
                csi0_dev1_dvdd = "dvdd-csi-18";
                csi0_dev1_dvdd_vol = <0x001b7740>;
                csi0_dev1_flash_used = <0x00>;
                csi0_dev1_flash_type = <0x02>;
                csi0_dev1_flvdd = "vdd-csi-led";
                csi0_dev1_flvdd_vol = <0x00325aa0>;
                csi0_dev1_act_used = <0x00>;
                csi0_dev1_act_name = "ad5820_act";
                csi0_dev1_act_slave = <0x18>;
                status = "disabled";
                device_type = "csi0_dev1";
                csi0_dev1_afvdd;
                csi0_dev1_afvdd_vol;
                csi0_dev1_power_en;
                csi0_dev1_reset = <&pio 0x04 0x10 0x00 0x00 0x01 0x00>;
                csi0_dev1_pwdn = <&pio 0x04 0x11 0x00 0x00 0x01 0x00>;
                csi0_dev1_flash_en;
                csi0_dev1_flash_mode;
                csi0_dev1_af_pwdn;
            };
        };

        vdevice: vdevice@0 {
            compatible = "allwinner,sun50i-vdevice";
            pinctrl-names = "default";
            test-gpios = <&r_pio 0x0b 0x00 0x01 0x02 0x03 0x04>;
            status = "disabled";
            device_type = "vdevice";
            pinctrl-0 = <&vdevice_pins_a>;
        };

        onewire_device@0 {
            compatible = "w1-gpio";
            gpios = <&pio 0x2 0x8 0x0 0x0 0x0 0x0>;
            pinctrl-names = "default";
            pinctrl-0 = <&w1_pin_pins_a>;
            status = "okay";
        };

        cryptoengine: ce@1c15000 {
            compatible = "allwinner,sunxi-ce";
            reg = <0x00 0x01c15000 0x00 0x80 0x00 0x01c15800 0x00 0x80>;
            interrupts = <0x00 0x5e 0xff01 0x00 0x50 0xff01>;
            clock-frequency = <0x11e1a300 0x0bebc200>;
            clocks = <&clk_ce>, <&clk_pll_periph0x2>;
        };

        di: deinterlace@0x01e00000 {
            #address-cells = <0x01>;
            #size-cells = <0x00>;
            compatible = "allwinner,sunxi-deinterlace";
            reg = <0x00 0x01e00000 0x00 0x077c>;
            interrupts = <0x00 0x5d 0x04>;
            clocks = <&clk_deinterlace> ,<&clk_pll_periph0>;
            status = "okay";
            device_type = "di";
        };

        smc: smartcard@0x01c2c400 {
            #address-cells = <0x01>;
            #size-cells = <0x00>;
            compatible = "allwinner,sunxi-scr";
            reg = <0x00 0x01c2c400 0x00 0x0100>;
            interrupts = <0x00 0x53 0x04>;
            clocks = <&clk_scr>, <&clk_apb2>;
            clock-frequency = <0x016e3600>;
            pinctrl-names = "default";
            pinctrl-0 = <&scr_pins_a>;
            status = "okay";
            device_type = "smc";
            smc_used;
            smc_rst;
            smc_vppen;
            smc_vppp;
            smc_det;
            smc_vccen;
            smc_sck;
            smc_sda;
        };

        nmi: nmi@0x01f00c00 {
            #address-cells = <0x01>;
            #size-cells = <0x00>;
            compatible = "allwinner,sunxi-nmi";
            reg = <0x00 0x01f00c00 0x00 0x50>;
            nmi_irq_ctrl = <0x0c>;
            nmi_irq_en = <0x40>;
            nmi_irq_status = <0x10>;
            nmi_irq_mask = <0x50>;
            status = "okay";
        };

        pmu0: pmu0@0 {
            compatible = "allwinner,pmu0";
            device_type = "pmu0";
            pmu_batdeten = <0x01>;
            pmu_init_chgend_rate = <0x14>;
            pmu_init_chg_enabled = <0x01>;
            pmu_init_adc_freq = <0x0320>;
            pmu_init_adcts_freq = <0x0320>;
            pmu_init_chg_pretime = <0x46>;
            pmu_init_chg_csttime = <0x02d0>;
            pmu_batt_cap_correct = <0x01>;
            pmu_chg_end_on_en = <0x00>;
            pmu_pwroff_vol = <0x0ce4>;
            pmu_pwron_vol = <0x0a28>;
            pmu_powkey_off_delay_time = <0x00>;
            pmu_pwrok_time = <0x40>;
            pmu_reset_shutdown_en = <0x01>;
            pmu_restvol_adjust_time = <0x3c>;
            pmu_ocv_cou_adjust_time = <0x3c>;
            pmu_vbusen_func = <0x01>;
            pmu_reset = <0x00>;
            pmu_IRQ_wakeup = <0x01>;
            pmu_hot_shutdowm = <0x01>;
            pmu_inshort = <0x00>;
            pmu_bat_shutdown_ltf = <0x0c80>;
            pmu_bat_shutdown_htf = <0xed>;
            status = "okay";
            pmu_id = <0x06>;
            pmu_twi_addr = <0x34>;
            pmu_twi_id = <0x01>;
            pmu_irq_id = <0x40>;
            pmu_chg_ic_temp = <0x00>;
            pmu_battery_rdc = <0x58>;
            pmu_battery_cap = <0x12c0>;
            pmu_runtime_chgcur = <0x01c2>;
            pmu_suspend_chgcur = <0x05dc>;
            pmu_shutdown_chgcur = <0x05dc>;
            pmu_init_chgvol = <0x1068>;
            pmu_ac_vol = <0x0fa0>;
            pmu_ac_cur = <0x0dac>;
            pmu_usbpc_vol = <0x1130>;
            pmu_usbpc_cur = <0x01f4>;
            pmu_battery_warning_level1 = <0x0f>;
            pmu_battery_warning_level2 = <0x00>;
            pmu_chgled_func = <0x00>;
            pmu_chgled_type = <0x00>;
            pmu_bat_para1 = <0x00>;
            pmu_bat_para2 = <0x00>;
            pmu_bat_para3 = <0x00>;
            pmu_bat_para4 = <0x00>;
            pmu_bat_para5 = <0x00>;
            pmu_bat_para6 = <0x00>;
            pmu_bat_para7 = <0x01>;
            pmu_bat_para8 = <0x01>;
            pmu_bat_para9 = <0x02>;
            pmu_bat_para10 = <0x03>;
            pmu_bat_para11 = <0x04>;
            pmu_bat_para12 = <0x0a>;
            pmu_bat_para13 = <0x11>;
            pmu_bat_para14 = <0x1a>;
            pmu_bat_para15 = <0x29>;
            pmu_bat_para16 = <0x2e>;
            pmu_bat_para17 = <0x33>;
            pmu_bat_para18 = <0x38>;
            pmu_bat_para19 = <0x3b>;
            pmu_bat_para20 = <0x41>;
            pmu_bat_para21 = <0x45>;
            pmu_bat_para22 = <0x4b>;
            pmu_bat_para23 = <0x4f>;
            pmu_bat_para24 = <0x53>;
            pmu_bat_para25 = <0x59>;
            pmu_bat_para26 = <0x5f>;
            pmu_bat_para27 = <0x62>;
            pmu_bat_para28 = <0x64>;
            pmu_bat_para29 = <0x64>;
            pmu_bat_para30 = <0x64>;
            pmu_bat_para31 = <0x64>;
            pmu_bat_para32 = <0x64>;
            pmu_bat_temp_enable = <0x01>;
            pmu_bat_charge_ltf = <0x08d5>;
            pmu_bat_charge_htf = <0x0184>;
            pmu_bat_temp_para1 = <0x1d2a>;
            pmu_bat_temp_para2 = <0x1180>;
            pmu_bat_temp_para3 = <0x0dbe>;
            pmu_bat_temp_para4 = <0x0ae2>;
            pmu_bat_temp_para5 = <0x08af>;
            pmu_bat_temp_para6 = <0x06fc>;
            pmu_bat_temp_para7 = <0x05a8>;
            pmu_bat_temp_para8 = <0x03c9>;
            pmu_bat_temp_para9 = <0x0298>;
            pmu_bat_temp_para10 = <0x01d2>;
            pmu_bat_temp_para11 = <0x0189>;
            pmu_bat_temp_para12 = <0x014d>;
            pmu_bat_temp_para13 = <0x011b>;
            pmu_bat_temp_para14 = <0xf2>;
            pmu_bat_temp_para15 = <0xb3>;
            pmu_bat_temp_para16 = <0x86>;
            pmu_powkey_off_time = <0x1770>;
            pmu_powkey_off_func = <0x00>;
            pmu_powkey_off_en = <0x01>;
            pmu_powkey_long_time = <0x05dc>;
            pmu_powkey_on_time = <0x03e8>;
            power_start = <0x00>;
        };

        pmo_regu: regu@0 {
            compatible = "allwinner,pmu0_regu";
            regulator_count = <0x17>;
            status = "okay";
            device_type = "pmu0_regu";
            regulator1 = "axp81x_dcdc1 none vcc-nand vcc-emmc vcc-sdc vcc-usb-30 vcc-io vcc-pd";
            regulator2 = "axp81x_dcdc2 none vdd-cpua";
            regulator3 = "axp81x_dcdc3 none";
            regulator4 = "axp81x_dcdc4 none";
            regulator5 = "axp81x_dcdc5 none vcc-dram";
            regulator6 = "axp81x_dcdc6 none vdd-sys";
            regulator7 = "axp81x_dcdc7 none";
            regulator8 = "axp81x_rtc none";
            regulator9 = "axp81x_aldo1 none vdd-csi-led iovdd-csi vcc-pe";
            regulator10 = "axp81x_aldo2 none vcc-pl";
            regulator11 = "axp81x_aldo3 none vcc-avcc vcc-pll";
            regulator12 = "axp81x_dldo1 none vcc-hdmi-33";
            regulator13 = "axp81x_dldo2 none vcc-mipi";
            regulator14 = "axp81x_dldo3 none avdd-csi";
            regulator15 = "axp81x_dldo4 none vcc-deviceio";
            regulator16 = "axp81x_eldo1 none vcc-cpvdd vcc-wifi-io vcc-pc vcc-pg";
            regulator17 = "axp81x_eldo2 none vcc-lcd-0";
            regulator18 = "axp81x_eldo3 none dvdd-csi-18";
            regulator19 = "axp81x_fldo1 none vcc-hsic-12";
            regulator20 = "axp81x_fldo2 none vdd-cpus";
            regulator21 = "axp81x_gpio0ldo none vcc-ctp";
            regulator22 = "axp81x_gpio1ldo none";
            regulator23 = "axp81x_dc1sw none vcc-lvds vcc-dsi-33";
        };

        nand0: nand0@01c03000 {
            compatible = "allwinner,sun50i-nand";
            device_type = "nand0";
            reg = <0x00 0x01c03000 0x00 0x1000>;
            interrupts = <0x00 0x46 0x04>;
            clocks = <&clk_pll_periph0>, <&clk_nand>;
            pinctrl-names = "default", "sleep";
            pinctrl-0 = <&nand0_pins_a &nand0_pins_b>;
            pinctrl-1 = <&nand0_pins_c>;
            nand0_regulator1 = "vcc-nand";
            nand0_regulator2 = "none";
            nand0_cache_level = <0x55aaaa55>;
            nand0_flush_cache_num = <0x55aaaa55>;
            nand0_capacity_level = <0x55aaaa55>;
            nand0_id_number_ctl = <0x55aaaa55>;
            nand0_print_level = <0x55aaaa55>;
            nand0_p0 = <0x55aaaa55>;
            nand0_p1 = <0x55aaaa55>;
            nand0_p2 = <0x55aaaa55>;
            nand0_p3 = <0x55aaaa55>;
            status = "disabled";
            nand0_support_2ch = <0x00>;
        };

        sunxi_thermal_sensor: thermal_sensor {
            compatible = "allwinner,thermal_sensor";
            reg = <0x00 0x01c25000 0x00 0x0400>;
            interrupts = <0x00 0x1f 0x00>;
            clocks = <&clk_hosc>, <&clk_ths>;
            sensor_num = <0x03>;
            shut_temp = <0x78>;
            status = "okay";
            combine0: combine0 {
                #thermal-sensor-cells = <0x01>;
                combine_cnt = <0x03>;
                combine_type = "max";
                combine_chn = <0x00 0x01 0x02>;
                linux,phandle = <0x85>;
                phandle = <0x85>;
            };
        };

        cpu_budget_cooling: cpu_budget_cool {
            compatible = "allwinner,budget_cooling";
            #cooling-cells = <0x02>;
            status = "okay";
            state_cnt = <0x0a>;
            cluster_num = <0x01>;
            state0 = <0x00119400 0x04>;
            state1 = <0x0010d880 0x04>;
            state2 = <0x00101d00 0x04>;
            state3 = <0x000f6180 0x04>;
            state4 = <0x000ea600 0x04>;
            state5 = <0x000dea80 0x04>;
            state6 = <0x000c7380 0x04>;
            state7 = <0x0009e340 0x04>;
            state8 = <0x0009e340 0x02>;
            state9 = <0x0009e340 0x01>;
            linux,phandle = <0x87>;
            phandle = <0x87>;
        };

        gpu_cooling: gpu_cooling {
            compatible = "allwinner,gpu_cooling";
            reg = <0x00 0x00 0x00 0x00>;
            #cooling-cells = <0x02>;
            status = "okay";
            state_cnt = <0x03>;
            state0 = <0x00>;
            state1 = <0x0168>;
            state2 = <0x90>;
            linux,phandle = <0x8c>;
            phandle = <0x8c>;
        };

        thermal-zones {
            soc_thermal {
                polling-delay-passive = <0x01f4>;
                polling-delay = <0x07d0>;
                thermal-sensors = <0x85 0x00>;
                trips {
                    cpu_trip0: t0 {
                        temperature = <0x50>;
                        type = "passive";
                        hysteresis = <0x00>;
                        linux,phandle = <0x86>;
                        phandle = <0x86>;
                    };
                    cpu_trip1: t1 {
                        temperature = <0x55>;
                        type = "passive";
                        hysteresis = <0x00>;
                        linux,phandle = <0x88>;
                        phandle = <0x88>;
                    };
                    cpu_trip2: t2 {
                        temperature = <0x5a>;
                        type = "passive";
                        hysteresis = <0x00>;
                        linux,phandle = <0x89>;
                        phandle = <0x89>;
                    };
                    cpu_trip3: t3 {
                        temperature = <0x5f>;
                        type = "passive";
                        hysteresis = <0x00>;
                        linux,phandle = <0x8a>;
                        phandle = <0x8a>;
                    };
                    gpu_trip0: t4 {
                        temperature = <0x55>;
                        type = "passive";
                        hysteresis = <0x00>;
                        linux,phandle = <0x8b>;
                        phandle = <0x8b>;
                    };
                    gpu_trip1: t5 {
                        temperature = <0x5a>;
                        type = "passive";
                        hysteresis = <0x00>;
                        linux,phandle = <0x8d>;
                        phandle = <0x8d>;
                    };
                    gpu_trip2: t6 {
                        temperature = <0x6c>;
                        type = "critical";
                        hysteresis = <0x00>;
                    };
                };
                cooling-maps {
                    bind0 {
                        contribution = <0x00>;
                        trip = <&cpu_trip0>;
                        cooling-device = <&cpu_budget_cooling 0x01 0x01>;
                    };
                    bind1 {
                        contribution = <0x00>;
                        trip = <&cpu_trip1>;
                        cooling-device = <&cpu_budget_cooling 0x02 0x02>;
                    };
                    bind2 {
                        contribution = <0x00>;
                        trip = <&cpu_trip2>;
                        cooling-device = <&cpu_budget_cooling 0x03 0x06>;
                    };
                    bind3 {
                        contribution = <0x00>;
                        trip = <&cpu_trip3>;
                        cooling-device = <&cpu_budget_cooling 0x07 0x09>;
                    };
                    bind4 {
                        contribution = <0x00>;
                        trip = <&gpu_trip0>;
                        cooling-device = <&gpu_cooling 0x01 0x01>;
                    };
                    bind5 {
                        contribution = <0x00>;
                        trip = <&gpu_trip1>;
                        cooling-device = <&gpu_cooling 0x02 0x02>;
                    };
                };
            };
        };

        keyboard0: keyboard {
            compatible = "allwinner,keyboard_2000mv";
            reg = <0x00 0x01c21800 0x00 0x0400>;
            interrupts = <0x00 0x1e 0x00>;
            status = "okay";
            key_cnt = <0x05>;
            key1 = <0xf0 0x73>;
            key2 = <0x01f4 0x72>;
            key3 = <0x02bc 0x8b>;
            key4 = <0x037a 0x1c>;
            key5 = <0x07d0 0x66>;
        };

        gmac0: eth@01c30000 {
            compatible = "allwinner,sunxi-gmac";
            reg = <0x00 0x01c30000 
				0x00 0x00010000 
				0x00 0x01c00000 
				0x00 0x30>;
            pinctrl-names = "default";
            interrupts = <0x00 0x52 0x04>;
            interrupt-names = "gmacirq";
            clocks = <&clk_gmac>;
            clock-names = "gmac";
            phy-mode = "rmii";
            tx-delay = <0x03>;
            rx-delay = <0x00>;
            gmac_power1 = "axp81x_dc1sw:0";
            status = "okay";
            device_type = "gmac0";
            pinctrl-0 = <&gmac0_pins_a>;
            gmac_power2;
            gmac_power3;
        };
        product {
            device_type = "product";
            version = "100";
            machine = "evb";
        };
        platform {
            device_type = "platform";
            eraseflag = <0x01>;
        };
        target {
            device_type = "target";
            boot_clock = <0x03f0>;
            storage_type = <0xffffffff>;
            burn_key = <0x00>;
        };
        power_sply {
            device_type = "power_sply";
            dcdc1_vol = <0x000f4f24>;
            dcdc2_vol = <0x000f468c>;
            dcdc6_vol = <0x000f468c>;
            aldo1_vol = <0x0af0>;
            aldo2_vol = <0x000f4948>;
            aldo3_vol = <0x000f4df8>;
            dldo1_vol = <0x0ce4>;
            dldo2_vol = <0x0ce4>;
            dldo3_vol = <0x0af0>;
            dldo4_vol = <0x000f4f24>;
            eldo1_vol = <0x000f4948>;
            eldo2_vol = <0x0708>;
            eldo3_vol = <0x0708>;
            fldo1_vol = <0x04b0>;
            fldo2_vol = <0x000f468c>;
            gpio0_vol = <0x0c1c>;
        };
        card_boot {
            device_type = "card_boot";
            logical_start = <0xa000>;
            sprite_gpio0;
        };
        pm_para {
            device_type = "pm_para";
            standby_mode = <0x01>;
        };
        card0_boot_para {
            device_type = "card0_boot_para";
            card_ctrl = <0x00>;
            card_high_speed = <0x01>;
            card_line = <0x04>;
            pinctrl-0 = <&card0_boot_para_pins_a>;
        };
        card2_boot_para {
            device_type = "card2_boot_para";
            sdc_io_1v8 = <0x01>;
            card_ctrl = <0x02>;
            card_high_speed = <0x01>;
            card_line = <0x08>;
            pinctrl-0 = <&card2_boot_para_pins_a>;
            sdc_ex_dly_used = <0x02>;
        };
        twi_para {
            device_type = "twi_para";
            twi_port = <0x00>;
            pinctrl-0 = <&twi_para_pins_a>;
        };
        uart_para {
            device_type = "uart_para";
            uart_debug_port = <0x00>;
            pinctrl-0 = <&uart_para_pins_a>;
        };
        jtag_para {
            device_type = "jtag_para";
            jtag_enable = <0x01>;
            pinctrl-0 = <&jtag_para_pins_a>;
        };
        clock {
            device_type = "clock";
            pll4 = <0x012c>;
            pll6 = <0x0258>;
            pll8 = <0x0168>;
            pll9 = <0x0129>;
            pll10 = <0x0108>;
        };
        rtp_para {
            device_type = "rtp_para";
            rtp_used = <0x00>;
            rtp_screen_size = <0x05>;
            rtp_regidity_level = <0x05>;
            rtp_press_threshold_enable = <0x00>;
            rtp_press_threshold = <0x1f40>;
            rtp_sensitive_level = <0x0f>;
            rtp_exchange_x_y_flag = <0x00>;
        };
        ctp {
            device_type = "ctp";
            compatible = "allwinner,sun50i-ctp-para";
            status = "disabled";
            ctp_name = "gt911_DB";
            ctp_twi_id = <0x00>;
            ctp_twi_addr = <0x40>;
            ctp_screen_max_x = <0x0400>;
            ctp_screen_max_y = <0x0258>;
            ctp_revert_x_flag = <0x01>;
            ctp_revert_y_flag = <0x01>;
            ctp_exchange_x_y_flag = <0x00>;
            ctp_int_port = <&pio 0x07 0x04 0x06 0xffffffff 0xffffffff 0xffffffff>;
            ctp_wakeup = <&pio 0x07 0x0b 0x01 0xffffffff 0xffffffff 0x01>;
            ctp_power_ldo = "vcc-ctp";
            ctp_power_ldo_vol = <0x0ce4>;
            ctp_power_io;
        };
        ctp_list {
            device_type = "ctp_list";
            compatible = "allwinner,sun50i-ctp-list";
            status = "okay";
            gslX680new = <0x01>;
            gt9xx_ts = <0x00>;
            gt9xxf_ts = <0x01>;
            gt9xxnew_ts = <0x00>;
            gt82x = <0x01>;
            zet622x = <0x01>;
            aw5306_ts = <0x01>;
        };
        tkey_para {
            device_type = "tkey_para";
            tkey_used = <0x00>;
            tkey_twi_id;
            tkey_twi_addr;
            tkey_int;
        };
        motor_para {
            device_type = "motor_para";
            motor_used = <0x00>;
            motor_shake = <0x31 0xfffe 0x03 
				0x01 0xffffffff 0xffffffff 0x01>;
        };
        tvout_para {
            device_type = "tvout_para";
            tvout_used;
            tvout_channel_num;
            tv_en;
        };
        tvin_para {
            device_type = "tvin_para";
            tvin_used;
            tvin_channel_num;
        };
        serial_feature {
            device_type = "serial_feature";
            sn_filename = "sn.txt";
        };
        gsensor {
            device_type = "gsensor";
            compatible = "allwinner,sun50i-gsensor-para";
            status = "okay";
            gsensor_twi_id = <0x01>;
            gsensor_twi_addr = <0x1d>;
            gsensor_vcc_io = "vcc-deviceio";
            gsensor_vcc_io_val = <0x0ce4>;
            gsensor_int1 = <&pio 0x07 0x05 0x06 0x01 0xffffffff 0xffffffff>;
            gsensor_int2 = <&pio 0x07 0x06 0x06 0x01 0xffffffff 0xffffffff>;
        };
        gsensor_list {
            device_type = "gsensor_list";
            compatible = "allwinner,sun50i-gsensor-list-para";
            gsensor_list__used = <0x01>;
            lsm9ds0_acc_mag = <0x01>;
            bma250 = <0x01>;
            mma8452 = <0x01>;
            mma7660 = <0x01>;
            mma865x = <0x01>;
            afa750 = <0x01>;
            lis3de_acc = <0x01>;
            lis3dh_acc = <0x01>;
            kxtik = <0x01>;
            dmard10 = <0x00>;
            dmard06 = <0x01>;
            mxc622x = <0x01>;
            fxos8700 = <0x01>;
            lsm303d = <0x00>;
            sc7a30 = <0x01>;
        };
        3g_para {
            device_type = "3g_para";
            3g_used = <0x00>;
            3g_usbc_num = <0x02>;
            3g_uart_num = <0x00>;
            bb_vbat = <&r_pio 0x0b 0x03 0x01 0xffffffff 0xffffffff 0x00>;
            bb_host_wake = <&r_pio 0x0c 0x00 0x01 0xffffffff 0xffffffff 0x00>;
            bb_on = <&r_pio 0x0c 0x01 0x01 0xffffffff 0xffffffff 0x00>;
            bb_pwr_on = <&r_pio 0x0c 0x03 0x01 0xffffffff 0xffffffff 0x00>;
            bb_wake = <&r_pio 0x0c 0x04 0x01 0xffffffff 0xffffffff 0x00>;
            bb_rf_dis = <&r_pio 0x0c 0x05 0x01 0xffffffff 0xffffffff 0x00>;
            bb_rst = <&r_pio 0x0c 0x06 0x01 0xffffffff 0xffffffff 0x00>;
            3g_int;
        };
        gyroscopesensor {
            device_type = "gyroscopesensor";
            compatible = "allwinner,sun50i-gyr_sensors-para";
            status = "disabled";
            gy_twi_id = <0x02>;
            gy_twi_addr = <0x6a>;
            gy_int1 = <&pio 0x00 0x0a 0x06 0x01 0xffffffff 0xffffffff>;
            gy_int2;
        };
        gy_list {
            device_type = "gy_list";
            compatible = "allwinner,sun50i-gyr_sensors-list-para";
            status = "disabled";
            lsm9ds0_gyr = <0x01>;
            l3gd20_gyr = <0x00>;
            bmg160_gyr = <0x01>;
        };
        lightsensor {
            device_type = "lightsensor";
            compatible = "allwinner,sun50i-lsensors-para";
            status = "disabled";
            ls_twi_id = <0x02>;
            ls_twi_addr = <0x23>;
            ls_int = <&pio 0x00 0x0c 0x06 0x01 0xffffffff 0xffffffff>;
        };
        ls_list {
            device_type = "ls_list";
            compatible = "allwinner,sun50i-lsensors-list-para";
            status = "disabled";
            ltr_501als = <0x01>;
            jsa1212 = <0x00>;
            jsa1127 = <0x01>;
            stk3x1x = <0x00>;
        };
        compasssensor {
            device_type = "compasssensor";
            compatible = "allwinner,sun50i-compass-para";
            status = "disabled";
            compass_twi_id = <0x02>;
            compass_twi_addr = <0x0d>;
            compass_int = <&pio 0x00 0x0b 0x06 0x01 0xffffffff 0xffffffff>;
        };
        compass_list {
            device_type = "compass_list";
            compatible = "allwinner,sun50i-compass-list-para";
            status = "disabled";
            lsm9ds0 = <0x01>;
            lsm303d = <0x00>;
        };
        recovery_key {
            device_type = "recovery_key";
            key_max = <0x0c>;
            key_min = <0x0a>;
        };
        fastboot_key {
            device_type = "fastboot_key";
            key_max = <0x06>;
            key_min = <0x04>;
        };
    };
};
